[part 3 of 4: packages /PDU to /ComponentTypes]
AUTOSAR XML (schema 4-3-0)
package /PDU
  pdu ClampControl_KL_01_XIX_VLAN_FAS: length=8, transmission-mode-true-timing=cyclic-timing={time-offset=0.0, time-period=0.02}, unused-bit-pattern=0
    signal KL_DI_KL_58xd_XIX_ClampControl_KL_01_XIX_VLAN_FAS: start 12, 8 bit, little-endian, data-type-policy=OVERRIDE, i-signal-type=PRIMITIVE, init-value=254, base-type=BT_KL_DI_KL_58xd, invalid-value=Invalid_KL_DI_KL_58xd_XIX_ClampControl_KL_01_XIX_VLAN_FAS:255, compu {phys=raw for raw 0..253, 255=Cxff_Fehler, 254=Cxfe_Init}, range phys 0..253, raw 0..255, transfer-property=PENDING, to Zone_VR(timeout 0.5 s)  # Klemme 58xd Display- und Funkltionsbeleuchtung
    signal KL_DI_KL_58xs_XIX_ClampControl_KL_01_XIX_VLAN_FAS: start 20, 7 bit, little-endian, data-type-policy=OVERRIDE, i-signal-type=PRIMITIVE, init-value=126, base-type=BT_KL_DI_KL_58xs, invalid-value=Invalid_KL_DI_KL_58xs_XIX_ClampControl_KL_01_XIX_VLAN_FAS:127, compu {phys=raw for raw 0..100, 127=Cx7f_Fehler, 126=Cx7e_Init}, range phys 0..100, raw 0..127, transfer-property=PENDING, to Zone_VR(timeout 0.5 s)  # Klemme 58xs Suchbeleuchtung
    signal KL_KST_KL_15_XIX_ClampControl_KL_01_XIX_VLAN_FAS: start 27, 1 bit, little-endian, data-type-policy=OVERRIDE, i-signal-type=PRIMITIVE, init-value=0, base-type=BT_KL_KST_KL_15, compu {0=Cx0_Aus, 1=Cx1_Ein}, range raw 0..1, transfer-property=PENDING, to Zone_VR(timeout 0.5 s)  # Klemme 15: Zuendung (SW-Kl.15) (geroutet)
  pdu ClimateControl_01_XIX_VLAN_FAS: length=64, minimum-delay=0.01, transmission-mode-true-timing={cyclic-timing={time-offset=0.0, time-period=0.1}, event-controlled-timing={number-of-repetitions=0, repetition-period=0.0}}, unused-bit-pattern=0
    signal KL_Temp_Soll_hr_XIX_ClimateControl_01_XIX_VLAN_FAS: start 13, 5 bit, little-endian, data-type-policy=OVERRIDE, i-signal-type=PRIMITIVE, init-value=31, base-type=BT_KL_Temp_Soll_hr, compu {phys=raw*0.5+15.5 for raw 0..29, 30=Cx1e_Klima_OFF, 31=Cx1f_Init; unit Unit_DegreCelsi}, range phys 15.5..30 Unit_DegreCelsi, raw 0..31, unit=Unit_DegreCelsi, transfer-property=PENDING  # Eingestellte Solltemperatur hinten rechts für verteilte Komfortfunktionen
    signal KL_Temp_Soll_vl_XIX_ClimateControl_01_XIX_VLAN_FAS: start 18, 5 bit, little-endian, data-type-policy=OVERRIDE, i-signal-type=PRIMITIVE, init-value=31, base-type=BT_KL_Temp_Soll_vl, compu {phys=raw*0.5+15.5 for raw 0..29, 30=Cx1e_Klima_OFF, 31=Cx1f_Init; unit Unit_DegreCelsi}, range phys 15.5..30 Unit_DegreCelsi, raw 0..31, unit=Unit_DegreCelsi, transfer-property=PENDING  # Eingestellte Solltemperatur vorne links für verteilte Komfortfunktionen
    signal KL_Temp_Soll_vr_XIX_ClimateControl_01_XIX_VLAN_FAS: start 23, 5 bit, little-endian, data-type-policy=OVERRIDE, i-signal-type=PRIMITIVE, init-value=31, base-type=BT_KL_Temp_Soll_vr, compu {phys=raw*0.5+15.5 for raw 0..29, 31=Cx1f_Init, 30=Cx1e_Klima_OFF; unit Unit_DegreCelsi}, range phys 15.5..30 Unit_DegreCelsi, raw 0..31, unit=Unit_DegreCelsi, transfer-property=PENDING  # Eingestellte Solltemperatur vorne rechts für verteilte Komfortfunktionen
    signal KL_Umluftklappe_Status_XIX_ClimateControl_01_XIX_VLAN_FAS: start 28, 4 bit, little-endian, data-type-policy=OVERRIDE, i-signal-type=PRIMITIVE, init-value=14, base-type=BT_KL_Umluftklappe_Status, invalid-value=Invalid_KL_Umluftklappe_Status_XIX_ClimateControl_01_XIX_VLAN_FAS:15, compu {15=Cxf_Fehler, 8=Cx8_Teilumluft_80, 1=Cx1_Teilumluft_10, 0=Cx0_Frischluft, 9=Cx9_Teilumluft_90, 6=Cx6_Teilumluft_60, 14=Cxe_Init, 10=Cxa_Umluft, 4=Cx4_Teilumluft_40, 2=Cx2_Teilumluft_20, 7=Cx7_Teilumluft_70, 5=Cx5_Teilumluft_50, 3=Cx3_Teilumluft_30}, range raw 0..15, transfer-property=PENDING  # Status Umluftklappe
    signal KL_Innen_Temp_XIX_ClimateControl_01_XIX_VLAN_FAS: start 32, 8 bit, little-endian, data-type-policy=OVERRIDE, i-signal-type=PRIMITIVE, init-value=254, base-type=BT_KL_Innen_Temp, invalid-value=Invalid_KL_Innen_Temp_XIX_ClimateControl_01_XIX_VLAN_FAS:255, compu {phys=raw*0.5-50 for raw 0..252, 255=Cxff_Fehler, 254=Cxfe_nicht_verfuegbar, 253=Cxfd_nicht_verbaut; unit Unit_DegreCelsi}, range phys -50..76 Unit_DegreCelsi, raw 0..255, unit=Unit_DegreCelsi, transfer-property=PENDING  # Innentemperatur
    signal KL_I_Geblaese_XIX_ClimateControl_01_XIX_VLAN_FAS: start 40, 8 bit, little-endian, data-type-policy=OVERRIDE, i-signal-type=PRIMITIVE, init-value=0, base-type=BT_KL_I_Geblaese, invalid-value=Invalid_KL_I_Geblaese_XIX_ClimateControl_01_XIX_VLAN_FAS:255, compu {phys=raw*0.25 for raw 0..254, 255=Cxff_Fehler; unit Unit_Amper}, range phys 0..63.5 Unit_Amper, raw 0..255, unit=Unit_Amper, transfer-property=PENDING  # Stromaufnahme Gebläse
    signal ClActFan_perc_BlowerTarVal_S_XIX_ClimateControl_01_XIX_VLAN_FAS: start 48, 8 bit, little-endian, data-type-policy=OVERRIDE, i-signal-type=PRIMITIVE, init-value=0, base-type=BT_ClActFan_perc_BlowerTarVal_S, compu {phys=raw for raw 0..255; unit Unit_PerCent}, range phys 0..255 Unit_PerCent, raw 0..255, unit=Unit_PerCent, transfer-property=PENDING, to Zone_VR(timeout 1 s)  # Soll Wert des BLDC in Prozent
    signal ClHmi_st_StDfrst_S_XIX_ClimateControl_01_XIX_VLAN_FAS: start 56, 8 bit, little-endian, data-type-policy=OVERRIDE, i-signal-type=PRIMITIVE, init-value=0, base-type=BT_ClHmi_st_StDfrst_S, compu {phys=raw for raw 0..255; unit Unit_None}, range phys 0..255 Unit_None, raw 0..255, unit=Unit_None, transfer-property=PENDING, to Zone_VR(timeout 1 s)  # Aktueller Status Defrost UX
    signal ClHmi_T_CurTempFrntLe_S_XIX_ClimateControl_01_XIX_VLAN_FAS: start 64, 8 bit, little-endian, data-type-policy=OVERRIDE, i-signal-type=PRIMITIVE, init-value=0, base-type=BT_ClHmi_T_CurTempFrntLe_S, compu {phys=raw*0.1+10 for raw 0..255; unit Unit_DegreCelsi}, range phys 10..35.5 Unit_DegreCelsi, raw 0..255, unit=Unit_DegreCelsi, transfer-property=PENDING, to Zone_VR(timeout 1 s)  # Aktuell eingestellte Temperatur VL
    signal ClHmi_T_CurTempFrntRi_S_XIX_ClimateControl_01_XIX_VLAN_FAS: start 72, 8 bit, little-endian, data-type-policy=OVERRIDE, i-signal-type=PRIMITIVE, init-value=0, base-type=BT_ClHmi_T_CurTempFrntRi_S, compu {phys=raw*0.1+10 for raw 0..255; unit Unit_DegreCelsi}, range phys 10..35.5 Unit_DegreCelsi, raw 0..255, unit=Unit_DegreCelsi, transfer-property=PENDING, to Zone_VR(timeout 1 s)  # Aktuell eingestellte Temperatur VR
    signal ClHmi_T_CurTempRearLe_S_XIX_ClimateControl_01_XIX_VLAN_FAS: start 80, 8 bit, little-endian, data-type-policy=OVERRIDE, i-signal-type=PRIMITIVE, init-value=0, base-type=BT_ClHmi_T_CurTempRearLe_S, compu {phys=raw*0.1+10 for raw 0..255; unit Unit_DegreCelsi}, range phys 10..35.5 Unit_DegreCelsi, raw 0..255, unit=Unit_DegreCelsi, transfer-property=PENDING, to Zone_VR(timeout 1 s)  # Aktuell eingestellte Temperatur HL
    signal ClHmi_T_CurTempRearRi_S_XIX_ClimateControl_01_XIX_VLAN_FAS: start 88, 8 bit, little-endian, data-type-policy=OVERRIDE, i-signal-type=PRIMITIVE, init-value=0, base-type=BT_ClHmi_T_CurTempRearRi_S, compu {phys=raw*0.1+10 for raw 0..255; unit Unit_DegreCelsi}, range phys 10..35.5 Unit_DegreCelsi, raw 0..255, unit=Unit_DegreCelsi, transfer-property=PENDING, to Zone_VR(timeout 1 s)  # Aktuell eingestellte Temperatur HR
    signal KL_BT_Tuer_geoeffnet_XIX_ClimateControl_01_XIX_VLAN_FAS: start 96, 1 bit, little-endian, data-type-policy=OVERRIDE, i-signal-type=PRIMITIVE, init-value=0, base-type=BT_KL_BT_Tuer_geoeffnet, compu {1=Cx1_offen, 0=Cx0_geschlossen}, range raw 0..1, transfer-property=TRIGGERED-ON-CHANGE-WITHOUT-REPETITION  # Status Beifahrertuer (Routing)
    signal KL_FT_Tuer_geoeffnet_XIX_ClimateControl_01_XIX_VLAN_FAS: start 97, 1 bit, little-endian, data-type-policy=OVERRIDE, i-signal-type=PRIMITIVE, init-value=0, base-type=BT_KL_FT_Tuer_geoeffnet, compu {1=Cx1_offen, 0=Cx0_geschlossen}, range raw 0..1, transfer-property=TRIGGERED-ON-CHANGE-WITHOUT-REPETITION  # Status Tuer_offen (Routing)
    signal KL_HBFS_Tuer_geoeffnet_XIX_ClimateControl_01_XIX_VLAN_FAS: start 98, 1 bit, little-endian, data-type-policy=OVERRIDE, i-signal-type=PRIMITIVE, init-value=0, base-type=BT_KL_HBFS_Tuer_geoeffnet, compu {0=Cx0_geschlossen, 1=Cx1_offen}, range raw 0..1, transfer-property=TRIGGERED-ON-CHANGE-WITHOUT-REPETITION  # Status Beifahrertuer hinten (Routing)
    signal KL_HFS_Tuer_geoeffnet_XIX_ClimateControl_01_XIX_VLAN_FAS: start 99, 1 bit, little-endian, data-type-policy=OVERRIDE, i-signal-type=PRIMITIVE, init-value=0, base-type=BT_KL_HFS_Tuer_geoeffnet, compu {1=Cx1_offen, 0=Cx0_geschlossen}, range raw 0..1, transfer-property=TRIGGERED-ON-CHANGE-WITHOUT-REPETITION  # Status Fahrertuer hinten (Routing)
    signal KL_Geblaese_Status_XIX_ClimateControl_01_XIX_VLAN_FAS: start 100, 4 bit, little-endian, data-type-policy=OVERRIDE, i-signal-type=PRIMITIVE, init-value=14, base-type=BT_KL_Geblaese_Status, invalid-value=Invalid_KL_Geblaese_Status_XIX_ClimateControl_01_XIX_VLAN_FAS:15, compu {15=Cxf_Fehler, 14=Cxe_Init, 0=Cx0_Geblaese_aus, 1=Cx1_Geblaesestufe_10, 2=Cx2_Geblaesestufe_20, 3=Cx3_Geblaesestufe_30, 4=Cx4_Geblaesestufe_40, 5=Cx5_Geblaesestufe_50, 6=Cx6_Geblaesestufe_60, 7=Cx7_Geblaesestufe_70, 8=Cx8_Geblaesestufe_80, 9=Cx9_Geblaesestufe_90, 10=Cxa_Geblaesestufe_100}, range raw 0..15, transfer-property=PENDING  # Status Geblaese
    signal KL_Temp_Soll_hl_XIX_ClimateControl_01_XIX_VLAN_FAS: start 104, 5 bit, little-endian, data-type-policy=OVERRIDE, i-signal-type=PRIMITIVE, init-value=31, base-type=BT_KL_Temp_Soll_hl, compu {phys=raw*0.5+15.5 for raw 0..29, 31=Cx1f_Init, 30=Cx1e_Klima_OFF; unit Unit_DegreCelsi}, range phys 15.5..30 Unit_DegreCelsi, raw 0..31, unit=Unit_DegreCelsi, transfer-property=PENDING  # Eingestellte Solltemperatur hinten links für verteilte Komfortfunktionen
    signal ClHmi_st_BtnDfrst_S_XIX_ClimateControl_01_XIX_VLAN_FAS: start 109, 8 bit, little-endian, data-type-policy=OVERRIDE, i-signal-type=PRIMITIVE, init-value=0, base-type=BT_ClHmi_st_BtnDfrst_S, compu {phys=raw for raw 0..255; unit Unit_None}, range phys 0..255 Unit_None, raw 0..255, unit=Unit_None, transfer-property=PENDING  # Tastendruck Defrost
    signal ClAct_perc_FlapDfrstTarVal_XIX_ClimateControl_01_XIX_VLAN_FAS: start 117, 8 bit, little-endian, data-type-policy=OVERRIDE, i-signal-type=PRIMITIVE, init-value=0, base-type=BT_ClAct_perc_FlapDfrstTarVal, compu {phys=raw for raw 0..255; unit Unit_PerCent}, range phys 0..255 Unit_PerCent, raw 0..255, unit=Unit_PerCent, transfer-property=PENDING, to Zone_VR(timeout 1 s)  # Soll-Wert der Stellklappe Defrost in Prozent
    signal ClAct_perc_FlapTFrntLeTarVal_XIX_ClimateControl_01_XIX_VLAN_FAS: start 125, 8 bit, little-endian, data-type-policy=OVERRIDE, i-signal-type=PRIMITIVE, init-value=0, base-type=BT_ClAct_perc_FlapTFrntLeTarVal, compu {phys=raw for raw 0..255; unit Unit_PerCent}, range phys 0..255 Unit_PerCent, raw 0..255, unit=Unit_PerCent, transfer-property=PENDING, to Zone_VR(timeout 1 s)  # Soll-Wert der Stellklappe Temp VL in Prozent
    signal ClAct_perc_FlapTFrntRiTarVal_XIX_ClimateControl_01_XIX_VLAN_FAS: start 133, 8 bit, little-endian, data-type-policy=OVERRIDE, i-signal-type=PRIMITIVE, init-value=0, base-type=BT_ClAct_perc_FlapTFrntRiTarVal, compu {phys=raw for raw 0..255; unit Unit_PerCent}, range phys 0..255 Unit_PerCent, raw 0..255, unit=Unit_PerCent, transfer-property=PENDING, to Zone_VR(timeout 1 s)  # Soll-Wert der Stellklappe Temp VR in Prozent
    signal ClAct_perc_FlapTRearLeTarVal_XIX_ClimateControl_01_XIX_VLAN_FAS: start 141, 8 bit, little-endian, data-type-policy=OVERRIDE, i-signal-type=PRIMITIVE, init-value=0, base-type=BT_ClAct_perc_FlapTRearLeTarVal, compu {phys=raw for raw 0..255; unit Unit_PerCent}, range phys 0..255 Unit_PerCent, raw 0..255, unit=Unit_PerCent, transfer-property=PENDING, to Zone_VR(timeout 1 s)  # Soll-Wert der Stellklappe Temp HL in Prozent
    signal ClAct_perc_FlapTRearRiTarVal_XIX_ClimateControl_01_XIX_VLAN_FAS: start 149, 8 bit, little-endian, data-type-policy=OVERRIDE, i-signal-type=PRIMITIVE, init-value=0, base-type=BT_ClAct_perc_FlapTRearRiTarVal, compu {phys=raw for raw 0..255; unit Unit_PerCent}, range phys 0..255 Unit_PerCent, raw 0..255, unit=Unit_PerCent, transfer-property=PENDING, to Zone_VR(timeout 1 s)  # Soll-Wert der Stellklappe Temp HR in Prozent
    signal ClSens_SetBit1_S_XIX_ClimateControl_01_XIX_VLAN_FAS: start 157, 16 bit, little-endian, data-type-policy=OVERRIDE, i-signal-type=PRIMITIVE, init-value=0, base-type=BT_ClSens_SetBit1_S, compu {phys=raw for raw 0..65535; unit Unit_None}, range phys 0..65535 Unit_None, raw 0..65535, unit=Unit_None, transfer-property=PENDING, to Zone_VR(timeout 1 s)  # Aktivierung Climate Funktion
    signal ClSens_SetBit2_S_XIX_ClimateControl_01_XIX_VLAN_FAS: start 173, 16 bit, little-endian, data-type-policy=OVERRIDE, i-signal-type=PRIMITIVE, init-value=0, base-type=BT_ClSens_SetBit2_S, compu {phys=raw for raw 0..65535; unit Unit_None}, range phys 0..65535 Unit_None, raw 0..65535, unit=Unit_None, transfer-property=PENDING, to Zone_VR(timeout 1 s)  # Aktivierung Climate Funktion
    signal ClHmi_st_ClInfo_S_XIX_ClimateControl_01_XIX_VLAN_FAS: start 189, 8 bit, little-endian, data-type-policy=OVERRIDE, i-signal-type=PRIMITIVE, init-value=0, base-type=BT_ClHmi_st_ClInfo_S, invalid-value=Invalid_ClHmi_st_ClInfo_S_XIX_ClimateControl_01_XIX_VLAN_FAS:15, compu {15=Cxf_Fehler, 3=Cx3_HEATING, 0=Cx0_OFF, 2=Cx2_VENTILATION, 1=Cx1_COOLING}, range raw 0..15, transfer-property=TRIGGERED-ON-CHANGE-WITHOUT-REPETITION  # Status Climatisation
    signal ClStm_OpState_XIX_ClimateControl_01_XIX_VLAN_FAS: start 197, 8 bit, little-endian, data-type-policy=OVERRIDE, i-signal-type=PRIMITIVE, init-value=0, base-type=BT_ClStm_OpState, compu {phys=raw for raw 0..255; unit Unit_None}, range phys 0..255 Unit_None, raw 0..255, unit=Unit_None, transfer-property=PENDING, to Zone_VR(timeout 1 s)  # Aktueller Zustand der Klimasoftware
  pdu ClimateControl_02_XIX_VLAN_FAS: length=64, minimum-delay=0.005, transmission-mode-true-timing={cyclic-timing={time-offset=0.0, time-period=0.02}, event-controlled-timing={number-of-repetitions=0, repetition-period=0.0}}, unused-bit-pattern=0
    signal ClSensUIF_st_State_S_XIX_ClimateControl_02_XIX_VLAN_FAS: start 12, 8 bit, little-endian, data-type-policy=OVERRIDE, i-signal-type=PRIMITIVE, init-value=0, base-type=BT_ClSensUIF_st_State_S, compu {phys=raw for raw 0..255; unit Unit_None}, range phys 0..255 Unit_None, raw 0..255, unit=Unit_None, transfer-property=PENDING  # Status des UIF Sensors
    signal ClSensUIF_T_FilUIF_S_XIX_ClimateControl_02_XIX_VLAN_FAS: start 20, 16 bit, little-endian, data-type-policy=OVERRIDE, i-signal-type=PRIMITIVE, init-value=0, base-type=BT_ClSensUIF_T_FilUIF_S, compu {phys=raw*0.0625-2048 for raw 0..65520; unit Unit_DegreCelsi}, range phys -2048..2047 Unit_DegreCelsi, raw 0..65520, unit=Unit_DegreCelsi, transfer-property=PENDING  # Gefilterte Temperatur des UIF
    signal ClSensUIF_T_ValUIF_S_XIX_ClimateControl_02_XIX_VLAN_FAS: start 36, 16 bit, little-endian, data-type-policy=OVERRIDE, i-signal-type=PRIMITIVE, init-value=0, base-type=BT_ClSensUIF_T_ValUIF_S, compu {phys=raw*0.0625-2048 for raw 0..65520; unit Unit_DegreCelsi}, range phys -2048..2047 Unit_DegreCelsi, raw 0..65520, unit=Unit_DegreCelsi, transfer-property=PENDING  # Aktuelle Temperatur des UIF
    signal ClSensTemp_T_TempKGFrnt_S_XIX_ClimateControl_02_XIX_VLAN_FAS: start 52, 16 bit, little-endian, data-type-policy=OVERRIDE, i-signal-type=PRIMITIVE, init-value=0, base-type=BT_ClSensTemp_T_TempKGFrnt_S, compu {phys=raw*0.0625-2048 for raw 0..65520; unit Unit_DegreCelsi}, range phys -2048..2047 Unit_DegreCelsi, raw 0..65520, unit=Unit_DegreCelsi, transfer-property=PENDING  # Aktueller Wert diskreter Temperatursensor
    signal ClAct_perc_FlapDfrstCurVal_S_XIX_ClimateControl_02_XIX_VLAN_FAS: start 68, 8 bit, little-endian, data-type-policy=OVERRIDE, i-signal-type=PRIMITIVE, init-value=0, base-type=BT_ClAct_perc_FlapDfrstCurVal_S, compu {phys=raw for raw 0..255; unit Unit_PerCent}, range phys 0..255 Unit_PerCent, raw 0..255, unit=Unit_PerCent, transfer-property=PENDING  # Aktueller Wert der Stellklappe Defrost in Prozent
    signal ClAct_perc_FlapTFrntLeCurVal_XIX_ClimateControl_02_XIX_VLAN_FAS: start 76, 8 bit, little-endian, data-type-policy=OVERRIDE, i-signal-type=PRIMITIVE, init-value=0, base-type=BT_ClAct_perc_FlapTFrntLeCurVal, compu {phys=raw for raw 0..255; unit Unit_PerCent}, range phys 0..255 Unit_PerCent, raw 0..255, unit=Unit_PerCent, transfer-property=PENDING  # Aktueller Wert der Stellklappe Temp VL in Prozent
    signal ClAct_perc_FlapTFrntRiCurVal_XIX_ClimateControl_02_XIX_VLAN_FAS: start 84, 8 bit, little-endian, data-type-policy=OVERRIDE, i-signal-type=PRIMITIVE, init-value=0, base-type=BT_ClAct_perc_FlapTFrntRiCurVal, compu {phys=raw for raw 0..255; unit Unit_PerCent}, range phys 0..255 Unit_PerCent, raw 0..255, unit=Unit_PerCent, transfer-property=PENDING  # Aktueller Wert der Stellklappe Temp VR in Prozent
    signal ClAct_perc_FlapTRearLeCurVal_XIX_ClimateControl_02_XIX_VLAN_FAS: start 92, 8 bit, little-endian, data-type-policy=OVERRIDE, i-signal-type=PRIMITIVE, init-value=0, base-type=BT_ClAct_perc_FlapTRearLeCurVal, compu {phys=raw for raw 0..255; unit Unit_PerCent}, range phys 0..255 Unit_PerCent, raw 0..255, unit=Unit_PerCent, transfer-property=PENDING  # Aktueller Wert der Stellklappe Temp HL in Prozent
    signal ClAct_perc_FlapTRearRiCurVal_XIX_ClimateControl_02_XIX_VLAN_FAS: start 100, 8 bit, little-endian, data-type-policy=OVERRIDE, i-signal-type=PRIMITIVE, init-value=0, base-type=BT_ClAct_perc_FlapTRearRiCurVal, compu {phys=raw for raw 0..255; unit Unit_PerCent}, range phys 0..255 Unit_PerCent, raw 0..255, unit=Unit_PerCent, transfer-property=PENDING  # Aktueller Wert der Stellklappe Temp HR in Prozent
    signal ClAct_st_FlapDfrst_S_XIX_ClimateControl_02_XIX_VLAN_FAS: start 108, 8 bit, little-endian, data-type-policy=OVERRIDE, i-signal-type=PRIMITIVE, init-value=0, base-type=BT_ClAct_st_FlapDfrst_S, compu {phys=raw for raw 0..255; unit Unit_None}, range phys 0..255 Unit_None, raw 0..255, unit=Unit_None, transfer-property=PENDING  # Status der Stellklappe Defrost
    signal ClAct_st_FlapTempFrntLe_S_XIX_ClimateControl_02_XIX_VLAN_FAS: start 116, 8 bit, little-endian, data-type-policy=OVERRIDE, i-signal-type=PRIMITIVE, init-value=0, base-type=BT_ClAct_st_FlapTempFrntLe_S, compu {phys=raw for raw 0..255; unit Unit_None}, range phys 0..255 Unit_None, raw 0..255, unit=Unit_None, transfer-property=PENDING  # Status der Stellklappe Temp VL
    signal ClAct_st_FlapTempFrntRi_S_XIX_ClimateControl_02_XIX_VLAN_FAS: start 124, 8 bit, little-endian, data-type-policy=OVERRIDE, i-signal-type=PRIMITIVE, init-value=0, base-type=BT_ClAct_st_FlapTempFrntRi_S, compu {phys=raw for raw 0..255; unit Unit_None}, range phys 0..255 Unit_None, raw 0..255, unit=Unit_None, transfer-property=PENDING  # Status der Stellklappe Temp VR
    signal ClAct_st_FlapTempRearLe_S_XIX_ClimateControl_02_XIX_VLAN_FAS: start 132, 8 bit, little-endian, data-type-policy=OVERRIDE, i-signal-type=PRIMITIVE, init-value=0, base-type=BT_ClAct_st_FlapTempRearLe_S, compu {phys=raw for raw 0..255; unit Unit_None}, range phys 0..255 Unit_None, raw 0..255, unit=Unit_None, transfer-property=PENDING  # Status der Stellklappe Temp HL
    signal ClAct_st_FlapTRearRiDfrst_XIX_ClimateControl_02_XIX_VLAN_FAS: start 140, 8 bit, little-endian, data-type-policy=OVERRIDE, i-signal-type=PRIMITIVE, init-value=0, base-type=BT_ClAct_st_FlapTRearRiDfrst, compu {phys=raw for raw 0..255; unit Unit_None}, range phys 0..255 Unit_None, raw 0..255, unit=Unit_None, transfer-property=PENDING  # Status der Stellklappe Temp HR
    signal ClActFan_perc_BlowerCurVal_S_XIX_ClimateControl_02_XIX_VLAN_FAS: start 148, 8 bit, little-endian, data-type-policy=OVERRIDE, i-signal-type=PRIMITIVE, init-value=0, base-type=BT_ClActFan_perc_BlowerCurVal_S, compu {phys=raw for raw 0..255; unit Unit_PerCent}, range phys 0..255 Unit_PerCent, raw 0..255, unit=Unit_PerCent, transfer-property=PENDING  # Aktueller Wert des BLDC in Prozent
    signal ClActFan_st_BlowerSt_S_XIX_ClimateControl_02_XIX_VLAN_FAS: start 156, 8 bit, little-endian, data-type-policy=OVERRIDE, i-signal-type=PRIMITIVE, init-value=0, base-type=BT_ClActFan_st_BlowerSt_S, compu {phys=raw for raw 0..255; unit Unit_None}, range phys 0..255 Unit_None, raw 0..255, unit=Unit_None, transfer-property=PENDING  # Status des BLDC (Blower)
    signal ClHmi_SetBit1_S_XIX_ClimateControl_02_XIX_VLAN_FAS: start 164, 16 bit, little-endian, data-type-policy=OVERRIDE, i-signal-type=PRIMITIVE, init-value=0, base-type=BT_ClHmi_SetBit1_S, compu {phys=raw for raw 0..65535; unit Unit_None}, range phys 0..65535 Unit_None, raw 0..65535, unit=Unit_None, transfer-property=PENDING  # Aktivierung Climate Funktion
    signal ClHmi_SetBit2_S_XIX_ClimateControl_02_XIX_VLAN_FAS: start 180, 16 bit, little-endian, data-type-policy=OVERRIDE, i-signal-type=PRIMITIVE, init-value=0, base-type=BT_ClHmi_SetBit2_S, compu {phys=raw for raw 0..65535; unit Unit_None}, range phys 0..65535 Unit_None, raw 0..65535, unit=Unit_None, transfer-property=PENDING  # Aktivierung Climate Funktion
    signal ClCcpRear_no_SetDfrst_S_XIX_ClimateControl_02_XIX_VLAN_FAS: start 196, 8 bit, little-endian, data-type-policy=OVERRIDE, i-signal-type=PRIMITIVE, init-value=0, base-type=BT_ClCcpRear_no_SetDfrst_S, compu {phys=raw for raw 0..255}, range phys 0..255, raw 0..255, transfer-property=TRIGGERED-ON-CHANGE-WITHOUT-REPETITION  # Aktivierungstrigger Defrost über LIN Bedienpanel
    signal ClCcpRear_no_TarDfrst_S_XIX_ClimateControl_02_XIX_VLAN_FAS: start 204, 8 bit, little-endian, data-type-policy=OVERRIDE, i-signal-type=PRIMITIVE, init-value=0, base-type=BT_ClCcpRear_no_TarDfrst_S, compu {phys=raw for raw 0..255}, range phys 0..255, raw 0..255, transfer-property=TRIGGERED-ON-CHANGE-WITHOUT-REPETITION  # Aktivierungstarget Defrost über LIN Bedienpanel
    signal ClCcpRear_T_TarTempLe_XIX_ClimateControl_02_XIX_VLAN_FAS: start 212, 8 bit, little-endian, data-type-policy=OVERRIDE, i-signal-type=PRIMITIVE, init-value=0, base-type=BT_ClCcpRear_T_TarTempLe, compu {phys=raw*0.1+10 for raw 0..255; unit Unit_DegreCelsi}, range phys 10..35.5 Unit_DegreCelsi, raw 0..255, unit=Unit_DegreCelsi, transfer-property=PENDING  # Temperatur Hinten Links über LIN Bedienpanel
    signal ClCcpRear_T_TarTempRi_XIX_ClimateControl_02_XIX_VLAN_FAS: start 220, 8 bit, little-endian, data-type-policy=OVERRIDE, i-signal-type=PRIMITIVE, init-value=0, base-type=BT_ClCcpRear_T_TarTempRi, compu {phys=raw*0.1+10 for raw 0..255; unit Unit_DegreCelsi}, range phys 10..35.5 Unit_DegreCelsi, raw 0..255, unit=Unit_DegreCelsi, transfer-property=PENDING  # Temperatur Hinten Rechts über LIN Bedienpanel
  pdu KN_Zone_VR_XIX_VLAN_FAS: length=16, unused-bit-pattern=0
    signal Zone_VR_SNI_10_XIX_KN_Zone_VR_XIX_VLAN_FAS: start 18, 10 bit, little-endian, data-type-policy=OVERRIDE, i-signal-type=PRIMITIVE, init-value=271, base-type=BT_Zone_VR_SNI_10, compu {phys=raw for raw 0..1023}, range phys 0..1023, raw 0..1023, transfer-property=TRIGGERED  # Source Node-Identifier (SNI) identifiziert den Sender der NM-Botschaft (Knotenadresse) eindeutig im Fahrzeug
  pdu TME_01_XIX_VLAN_FAS: length=64, unused-bit-pattern=0
    signal TME_T_OutsideAirTemp_raw_XIX_TME_01_XIX_VLAN_FAS: start 12, 16 bit, little-endian, data-type-policy=OVERRIDE, i-signal-type=PRIMITIVE, init-value=0, base-type=BT_TME_T_OutsideAirTemp_raw, compu {phys=raw*0.1-40 for raw 0..1900; unit Unit_DegreCelsi}, range phys -40..150 Unit_DegreCelsi, raw 0..1900, unit=Unit_DegreCelsi, transfer-property=TRIGGERED  # Rohwert des Außentemperatursensors
package /IPDUGroup
  8 x i signal i pdu group:
    Zone_VR_XIX_VLAN_FAS_Rx: communication-direction=IN, communication-mode=CAN_Receive_All, i-signal-i-pdus=[ClampControl_KL_01_XIX_VLAN_FAS, ClimateControl_01_XIX_VLAN_FAS]
    Zone_VR_XIX_VLAN_FAS_Tx: communication-direction=OUT, communication-mode=CAN_Transmit_All, i-signal-i-pdus=[KN_Zone_VR_XIX_VLAN_FAS, ClimateControl_02_XIX_VLAN_FAS, TME_01_XIX_VLAN_FAS]
    Zone_VR_XIX_Zone_VR_LIN06_Rx: communication-direction=IN, communication-mode=CAN_Receive_All, i-signal-i-pdus=[KPHs_01_XIX_Zone_VR_LIN06, KPHs_02_XIX_Zone_VR_LIN06]
    Zone_VR_XIX_Zone_VR_LIN06_Tx: communication-direction=OUT, communication-mode=CAN_Transmit_All, i-signal-i-pdus=[KPHe_01_XIX_Zone_VR_LIN06, KPHe_02_XIX_Zone_VR_LIN06]
    Zone_VR_XIX_Zone_VR_LIN11_Rx: communication-direction=IN, communication-mode=CAN_Receive_All
      i-signal-i-pdus:
        ACTs_106a_Status_XIX_Zone_VR_LIN11
        ACTs_109a_Status_XIX_Zone_VR_LIN11
        ACTs_105a_Status_XIX_Zone_VR_LIN11
        ACTs_104a_Status_XIX_Zone_VR_LIN11
    Zone_VR_XIX_Zone_VR_LIN11_Tx: communication-direction=OUT, communication-mode=CAN_Transmit_All
      i-signal-i-pdus:
        ACTe_105a_Control_XIX_Zone_VR_LIN11
        ACTe_109a_Control_XIX_Zone_VR_LIN11
        ACTe_104a_Control_XIX_Zone_VR_LIN11
        ACTe_106a_Control_XIX_Zone_VR_LIN11
        ACTe_100a_Broadcast_Ctrl_XIX_Zone_VR_LIN11
    Zone_VR_XIX_Zone_VR_LIN12_Rx: communication-direction=IN, communication-mode=CAN_Receive_All, i-signal-i-pdus=[BLOWERs_01_XIX_Zone_VR_LIN12, BLOWERs_02_XIX_Zone_VR_LIN12, ACTs_102f_Status_XIX_Zone_VR_LIN12]
    Zone_VR_XIX_Zone_VR_LIN12_Tx: communication-direction=OUT, communication-mode=CAN_Transmit_All
      i-signal-i-pdus:
        BLOWERe_01_XIX_Zone_VR_LIN12
        ACTe_102f_Control_XIX_Zone_VR_LIN12
        ACTe_100f_Broadcast_Ctrl_XIX_Zone_VR_LIN12
package /BaseType
  363 x base type, all with category=FIXED_LENGTH, base-type-size=8, base-type-encoding=NONE:
    BT_ACT102f_Adresse_Aktuator
    BT_ACT102f_Blockierung_aufgetreten
    BT_ACT102f_Drehrichtung
    BT_ACT102f_el_Defekt
    BT_ACT102f_Geschwindigkeitsstatus
    BT_ACT102f_Ist_Position_Aktuator
    BT_ACT102f_Notlauf_aufgetreten
    BT_ACT102f_Notlauffreigabe
    BT_ACT102f_Notlaufposition
    BT_ACT102f_Positionsvorgabe_Status
    BT_ACT102f_Reset
    BT_ACT102f_ResponseError
    BT_ACT102f_Selbsthaltemoment
    BT_ACT102f_Sonderfunktionen
    BT_ACT102f_Spulenbestromung
    BT_ACT102f_Stopmodus
    BT_ACT102f_Uebertemperatur
    BT_ACT102f_Variante
    BT_ACT102f_Verfahrrichtung
    BT_ACT102f_Versorgungsspannung
    BT_ACT104a_Adresse_Aktuator
    BT_ACT104a_Blockierung_aufgetreten
    BT_ACT104a_Drehrichtung
    BT_ACT104a_el_Defekt
    BT_ACT104a_Geschwindigkeitsstatus
    BT_ACT104a_Ist_Position_Aktuator
    BT_ACT104a_Notlauf_aufgetreten
    BT_ACT104a_Notlauffreigabe
    BT_ACT104a_Notlaufposition
    BT_ACT104a_Positionsvorgabe_Status
    BT_ACT104a_Reset
    BT_ACT104a_ResponseError
    BT_ACT104a_Selbsthaltemoment
    BT_ACT104a_Sonderfunktionen
    BT_ACT104a_Spulenbestromung
    BT_ACT104a_Stopmodus
    BT_ACT104a_Uebertemperatur
    BT_ACT104a_Variante
    BT_ACT104a_Verfahrrichtung
    BT_ACT104a_Versorgungsspannung
    BT_ACT105a_Adresse_Aktuator
    BT_ACT105a_Blockierung_aufgetreten
    BT_ACT105a_Drehrichtung
    BT_ACT105a_el_Defekt
    BT_ACT105a_Geschwindigkeitsstatus
    BT_ACT105a_Ist_Position_Aktuator
    BT_ACT105a_Notlauf_aufgetreten
    BT_ACT105a_Notlauffreigabe
    BT_ACT105a_Notlaufposition
    BT_ACT105a_Positionsvorgabe_Status
    BT_ACT105a_Reset
    BT_ACT105a_ResponseError
    BT_ACT105a_Selbsthaltemoment
    BT_ACT105a_Sonderfunktionen
    BT_ACT105a_Spulenbestromung
    BT_ACT105a_Stopmodus
    BT_ACT105a_Uebertemperatur
    BT_ACT105a_Variante
    BT_ACT105a_Verfahrrichtung
    BT_ACT105a_Versorgungsspannung
    BT_ACT106a_Adresse_Aktuator
    BT_ACT106a_Blockierung_aufgetreten
    BT_ACT106a_Drehrichtung
    BT_ACT106a_el_Defekt
    BT_ACT106a_Geschwindigkeitsstatus
    BT_ACT106a_Ist_Position_Aktuator
    BT_ACT106a_Notlauf_aufgetreten
    BT_ACT106a_Notlauffreigabe
    BT_ACT106a_Notlaufposition
    BT_ACT106a_Positionsvorgabe_Status
    BT_ACT106a_Reset
    BT_ACT106a_ResponseError
    BT_ACT106a_Selbsthaltemoment
    BT_ACT106a_Sonderfunktionen
    BT_ACT106a_Spulenbestromung
    BT_ACT106a_Stopmodus
    BT_ACT106a_Uebertemperatur
    BT_ACT106a_Variante
    BT_ACT106a_Verfahrrichtung
    BT_ACT106a_Versorgungsspannung
    BT_ACT109a_Adresse_Aktuator
    BT_ACT109a_Blockierung_aufgetreten
    BT_ACT109a_Drehrichtung
    BT_ACT109a_el_Defekt
    BT_ACT109a_Geschwindigkeitsstatus
    BT_ACT109a_Ist_Position_Aktuator
    BT_ACT109a_Notlauf_aufgetreten
    BT_ACT109a_Notlauffreigabe
    BT_ACT109a_Notlaufposition
    BT_ACT109a_Positionsvorgabe_Status
    BT_ACT109a_Reset
    BT_ACT109a_ResponseError
    BT_ACT109a_Selbsthaltemoment
    BT_ACT109a_Sonderfunktionen
    BT_ACT109a_Spulenbestromung
    BT_ACT109a_Stopmodus
    BT_ACT109a_Uebertemperatur
    BT_ACT109a_Variante
    BT_ACT109a_Verfahrrichtung
    BT_ACT109a_Versorgungsspannung
    BT_BLOWER_DIAG_FLAG1
    BT_BLOWER_DIAG_FLAG2
    BT_BLOWER_IBATT
    BT_BLOWER_ROTATION_SPEED
    BT_BLOWER_STATUS_MOTOR
    BT_BLOWER_SUPPLIER
    BT_BLOWER_TEMPERATURE
    BT_BLOWER_TORQUE
    BT_BLOWER_UBATT
    BT_BLOWER_UMOTOR
    BT_ClAct_perc_FlapDfrstCurVal_S
    BT_ClAct_perc_FlapDfrstTarVal
    BT_ClAct_perc_FlapTFrntLeCurVal
    BT_ClAct_perc_FlapTFrntLeTarVal
    BT_ClAct_perc_FlapTFrntRiCurVal
    BT_ClAct_perc_FlapTFrntRiTarVal
    BT_ClAct_perc_FlapTRearLeCurVal
    BT_ClAct_perc_FlapTRearLeTarVal
    BT_ClAct_perc_FlapTRearRiCurVal
    BT_ClAct_perc_FlapTRearRiTarVal
    BT_ClAct_st_FlapDfrst_S
    BT_ClAct_st_FlapTempFrntLe_S
    BT_ClAct_st_FlapTempFrntRi_S
    BT_ClAct_st_FlapTempRearLe_S
    BT_ClAct_st_FlapTRearRiDfrst
    BT_ClActFan_perc_BlowerCurVal_S
    BT_ClActFan_perc_BlowerTarVal_S
    BT_ClActFan_st_BlowerSt_S
    BT_ClCcpRear_no_SetDfrst_S
    BT_ClCcpRear_no_TarDfrst_S
    BT_ClCcpRear_T_TarTempLe
    BT_ClCcpRear_T_TarTempRi
    BT_ClHmi_SetBit1_S
    BT_ClHmi_SetBit2_S
    BT_ClHmi_st_BtnDfrst_S
    BT_ClHmi_st_ClInfo_S
    BT_ClHmi_st_StDfrst_S
    BT_ClHmi_T_CurTempFrntLe_S
    BT_ClHmi_T_CurTempFrntRi_S
    BT_ClHmi_T_CurTempRearLe_S
    BT_ClHmi_T_CurTempRearRi_S
    BT_ClSens_SetBit1_S
    BT_ClSens_SetBit2_S
    BT_ClSensTemp_T_TempKGFrnt_S
    BT_ClSensUIF_st_State_S
    BT_ClSensUIF_T_FilUIF_S
    BT_ClSensUIF_T_ValUIF_S
    BT_ClStm_OpState
    BT_Geblaese_ResponseError
    BT_KBT_CODE_VEHICLE
    BT_KBT_RAMP
    BT_KBT_RX_FREQUENCY
    BT_KBT_SAFETY_SPEED
    BT_KBT_SPEED
    BT_KL_BT_Tuer_geoeffnet
    BT_KL_DI_KL_58xd
    BT_KL_DI_KL_58xs
    BT_KL_FT_Tuer_geoeffnet
    BT_KL_Geblaese_Status
    BT_KL_HBFS_Tuer_geoeffnet
    BT_KL_HFS_Tuer_geoeffnet
    BT_KL_I_Geblaese
    BT_KL_Innen_Temp
    BT_KL_KST_KL_15
    BT_KL_Temp_Soll_hl
    BT_KL_Temp_Soll_hr
    BT_KL_Temp_Soll_vl
    BT_KL_Temp_Soll_vr
    BT_KL_Umluftklappe_Status
    BT_KPH_01_Init
    BT_KPH_AC
    BT_KPH_AC_max
    BT_KPH_Auto_li
    BT_KPH_Auto_re
    BT_KPH_Beduftung
    BT_KPH_ECO
    BT_KPH_ECO_links
    BT_KPH_ECO_rechts
    BT_KPH_Flaechenheizung
    BT_KPH_Geblaese_Auto_li
    BT_KPH_Geblaese_Auto_re
    BT_KPH_Geblaese_Stufe_li
    BT_KPH_Geblaese_Stufe_re
    BT_KPH_Init
    BT_KPH_Ionisator
    BT_KPH_Klima_Menue_MMI
    BT_KPH_Lautsprecher
    BT_KPH_Lokalaktiv
    BT_KPH_Luftverteilung_Auto_li
    BT_KPH_Luftverteilung_Auto_re
    BT_KPH_Luftverteilung_Mitte_li
    BT_KPH_Luftverteilung_Mitte_re
    BT_KPH_Luftverteilung_Oben_li
    BT_KPH_Luftverteilung_Oben_re
    BT_KPH_Luftverteilung_Unten_li
    BT_KPH_Luftverteilung_Unten_re
    BT_KPH_Neigungssensor
    BT_KPH_Off
    BT_KPH_Panel_Error
    BT_KPH_ResponseError
    BT_KPH_Sitzheizung_li
    BT_KPH_Sitzheizung_re
    BT_KPH_Sitzlueftung_li
    BT_KPH_Sitzlueftung_re
    BT_KPH_Status_Spannung
    BT_KPH_Sync
    BT_KPH_Tasten_Fehler
    BT_KPH_Temp_li
    BT_KPH_Temp_Platine
    BT_KPH_Temp_re
    BT_KPH_Umluft
    BT_KPH_Umprog_Sektor_Nr
    BT_KPH_Umprog_Symbol_Nr
    BT_KPHe_Auto_Toggle
    BT_KPHe_Einheit
    BT_KPHe_Fondbedienung
    BT_KPHe_Funktion_AC
    BT_KPHe_Funktion_AC_max
    BT_KPHe_Funktion_Auto_li
    BT_KPHe_Funktion_Auto_re
    BT_KPHe_Funktion_Beduftung
    BT_KPHe_Funktion_Defrost
    BT_KPHe_Funktion_ECO
    BT_KPHe_Funktion_ECO_Zone
    BT_KPHe_Funktion_Flaechenheizung
    BT_KPHe_Funktion_Frontbedienung
    BT_KPHe_Funktion_Halbkreis_li
    BT_KPHe_Funktion_Halbkreis_re
    BT_KPHe_Funktion_Ionisator
    BT_KPHe_Funktion_Kindersicherung
    BT_KPHe_Funktion_Off
    BT_KPHe_Funktion_Sync
    BT_KPHe_Funktion_Umluft
    BT_KPHe_Funktionsbeleuchtung
    BT_KPHe_Fzg_Steigung
    BT_KPHe_Geblaese_Auto_li
    BT_KPHe_Geblaese_Auto_re
    BT_KPHe_Geblaese_Begrenzung
    BT_KPHe_Geblaese_Stufe_li
    BT_KPHe_Geblaese_Stufe_re
    BT_KPHe_LCD
    BT_KPHe_Lenker_Position
    BT_KPHe_Luftverteilung_Auto_li
    BT_KPHe_Luftverteilung_Auto_re
    BT_KPHe_Luftverteilung_Mitte_li
    BT_KPHe_Luftverteilung_Mitte_re
    BT_KPHe_Luftverteilung_Oben_li
    BT_KPHe_Luftverteilung_Oben_re
    BT_KPHe_Luftverteilung_Unten_li
    BT_KPHe_Luftverteilung_Unten_re
    BT_KPHe_QBit_Steigung
    BT_KPHe_Radio_Frequenz
    BT_KPHe_Sitzheizung_li
    BT_KPHe_Sitzheizung_re
    BT_KPHe_Sitzlueftung_li
    BT_KPHe_Sitzlueftung_re
    BT_KPHe_Stellgliedtest
    BT_KPHe_Suchbeleuchtung
    BT_KPHe_Symbol_Luftmenge_li
    BT_KPHe_Symbol_Luftmenge_re
    BT_KPHe_Symbol_Luftverteilung_li
    BT_KPHe_Symbol_Luftverteilung_re
    BT_KPHe_Symbol_Sitzheizung_li
    BT_KPHe_Symbol_Sitzheizung_re
    BT_KPHe_Symbol_Sitzlueftung_li
    BT_KPHe_Symbol_Sitzlueftung_re
    BT_KPHe_Temp_li
    BT_KPHe_Temp_re
    BT_KPHe_TFT
    BT_STRG100a_Adresse
    BT_STRG100a_Clear_Event_Flags
    BT_STRG100a_Drehrichtung
    BT_STRG100a_Freig_Blockiererkennung
    BT_STRG100a_Geschwindigkeitsvorgabe
    BT_STRG100a_Notlauffreigabe
    BT_STRG100a_Notlaufposition
    BT_STRG100a_PrgDaten_speichern
    BT_STRG100a_Select_Positionsvorgabe
    BT_STRG100a_Soll_Position
    BT_STRG100a_Spulenhaltebestromung
    BT_STRG100a_Start_Position
    BT_STRG100a_Stopmodus
    BT_STRG100f_Adresse
    BT_STRG100f_Clear_Event_Flags
    BT_STRG100f_Drehrichtung
    BT_STRG100f_Freig_Blockiererkennung
    BT_STRG100f_Geschwindigkeitsvorgabe
    BT_STRG100f_Notlauffreigabe
    BT_STRG100f_Notlaufposition
    BT_STRG100f_PrgDaten_speichern
    BT_STRG100f_Select_Positionsvorgabe
    BT_STRG100f_Soll_Position
    BT_STRG100f_Spulenhaltebestromung
    BT_STRG100f_Start_Position
    BT_STRG100f_Stopmodus
    BT_STRG102f_Adresse
    BT_STRG102f_Clear_Event_Flags
    BT_STRG102f_Drehrichtung
    BT_STRG102f_Freig_Blockiererkennung
    BT_STRG102f_Geschwindigkeitsvorgabe
    BT_STRG102f_Notlauffreigabe
    BT_STRG102f_Notlaufposition
    BT_STRG102f_PrgDaten_speichern
    BT_STRG102f_Select_Positionsvorgabe
    BT_STRG102f_Soll_Position
    BT_STRG102f_Spulenhaltebestromung
    BT_STRG102f_Start_Position
    BT_STRG102f_Stopmodus
    BT_STRG104a_Adresse
    BT_STRG104a_Clear_Event_Flags
    BT_STRG104a_Drehrichtung
    BT_STRG104a_Freig_Blockiererkennung
    BT_STRG104a_Geschwindigkeitsvorgabe
    BT_STRG104a_Notlauffreigabe
    BT_STRG104a_Notlaufposition
    BT_STRG104a_PrgDaten_speichern
    BT_STRG104a_Select_Positionsvorgabe
    BT_STRG104a_Soll_Position
    BT_STRG104a_Spulenhaltebestromung
    BT_STRG104a_Start_Position
    BT_STRG104a_Stopmodus
    BT_STRG105a_Adresse
    BT_STRG105a_Clear_Event_Flags
    BT_STRG105a_Drehrichtung
    BT_STRG105a_Freig_Blockiererkennung
    BT_STRG105a_Geschwindigkeitsvorgabe
    BT_STRG105a_Notlauffreigabe
    BT_STRG105a_Notlaufposition
    BT_STRG105a_PrgDaten_speichern
    BT_STRG105a_Select_Positionsvorgabe
    BT_STRG105a_Soll_Position
    BT_STRG105a_Spulenhaltebestromung
    BT_STRG105a_Start_Position
    BT_STRG105a_Stopmodus
    BT_STRG106a_Adresse
    BT_STRG106a_Clear_Event_Flags
    BT_STRG106a_Drehrichtung
    BT_STRG106a_Freig_Blockiererkennung
    BT_STRG106a_Geschwindigkeitsvorgabe
    BT_STRG106a_Notlauffreigabe
    BT_STRG106a_Notlaufposition
    BT_STRG106a_PrgDaten_speichern
    BT_STRG106a_Select_Positionsvorgabe
    BT_STRG106a_Soll_Position
    BT_STRG106a_Spulenhaltebestromung
    BT_STRG106a_Start_Position
    BT_STRG106a_Stopmodus
    BT_STRG109a_Adresse
    BT_STRG109a_Clear_Event_Flags
    BT_STRG109a_Drehrichtung
    BT_STRG109a_Freig_Blockiererkennung
    BT_STRG109a_Geschwindigkeitsvorgabe
    BT_STRG109a_Notlauffreigabe
    BT_STRG109a_Notlaufposition
    BT_STRG109a_PrgDaten_speichern
    BT_STRG109a_Select_Positionsvorgabe
    BT_STRG109a_Soll_Position
    BT_STRG109a_Spulenhaltebestromung
    BT_STRG109a_Start_Position
    BT_STRG109a_Stopmodus
    BT_TME_T_OutsideAirTemp_raw
    BT_Zone_VR_SNI_10
    BT_SignalVoid
package /Unit
  8 x unit:
    Unit_Unit_Amper: display-name=Unit_Amper, factor-si-to-unit=1.0, physical-dimension=PD_siAmpere
    Unit_Unit_DegreCelsi: display-name=Unit_DegreCelsi, factor-si-to-unit=1.0, offset-si-to-unit=-273.2, physical-dimension=PD_siKelvin
    Unit_Unit_KiloHertz: display-name=Unit_KiloHertz, factor-si-to-unit=0.001, physical-dimension=PD_siPerSecond
    Unit_Unit_MinutInver: display-name=Unit_MinutInver, factor-si-to-unit=60.0, physical-dimension=PD_siPerSecond
    Unit_Unit_NewtoMeter: display-name=Unit_NewtoMeter, factor-si-to-unit=1.0, physical-dimension=PD_siNewtonMeter
    Unit_Unit_None: display-name=Unit_None, factor-si-to-unit=1.0, physical-dimension=PD_siNone
    Unit_Unit_PerCent: display-name=Unit_PerCent, factor-si-to-unit=1.0, physical-dimension=PD_siNone
    Unit_Unit_Volt: display-name=Unit_Volt, factor-si-to-unit=1.0, physical-dimension=PD_siVolt
package /PhysicalDimension
  6 x physical dimension:
    PD_siAmpere: current-exp=1
    PD_siKelvin: temperature-exp=1
    PD_siNewtonMeter: length-exp=2, mass-exp=1, time-exp=-2
    PD_siNone
    PD_siPerSecond: time-exp=-1
    PD_siVolt: length-exp=2, mass-exp=1, time-exp=-1, current-exp=-1
package /Interfaces
  339 x sender receiver interface:
    IF_BLOWER_TEMPERATURE
      data DE_BLOWER_TEMPERATURE: type=uint8
    IF_KBT_RAMP
      data DE_KBT_RAMP: type=uint8
    IF_KBT_RX_FREQUENCY
      data DE_KBT_RX_FREQUENCY: type=uint16
    IF_KBT_SPEED
      data DE_KBT_SPEED: type=uint8
    IF_KBT_CODE_VEHICLE
      data DE_KBT_CODE_VEHICLE: type=uint8
    IF_KBT_SAFETY_SPEED
      data DE_KBT_SAFETY_SPEED: type=uint8
    IF_BLOWER_UBATT
      data DE_BLOWER_UBATT: type=uint8
    IF_BLOWER_UMOTOR
      data DE_BLOWER_UMOTOR: type=uint8
    IF_BLOWER_SUPPLIER
      data DE_BLOWER_SUPPLIER: type=uint8
    IF_BLOWER_STATUS_MOTOR
      data DE_BLOWER_STATUS_MOTOR: type=uint8
    IF_BLOWER_ROTATION_SPEED
      data DE_BLOWER_ROTATION_SPEED: type=uint8
    IF_BLOWER_IBATT
      data DE_BLOWER_IBATT: type=uint8
    IF_BLOWER_DIAG_FLAG2
      data DE_BLOWER_DIAG_FLAG2: type=uint8
    IF_BLOWER_DIAG_FLAG1
      data DE_BLOWER_DIAG_FLAG1: type=uint8
    IF_KPHe_Funktion_Halbkreis_li
      data DE_KPHe_Funktion_Halbkreis_li: type=boolean
    IF_KPHe_Funktion_Off
      data DE_KPHe_Funktion_Off: type=boolean
    IF_KPHe_Funktion_Ionisator
      data DE_KPHe_Funktion_Ionisator: type=boolean
    IF_KPHe_Funktion_Sync
      data DE_KPHe_Funktion_Sync: type=boolean
    IF_KPHe_Funktionsbeleuchtung
      data DE_KPHe_Funktionsbeleuchtung: type=boolean
    IF_KPHe_Geblaese_Stufe_li
      data DE_KPHe_Geblaese_Stufe_li: type=uint8
    IF_KPHe_Geblaese_Stufe_re
      data DE_KPHe_Geblaese_Stufe_re: type=uint8
    IF_KPHe_Funktion_Umluft
      data DE_KPHe_Funktion_Umluft: type=boolean
    IF_KPHe_Funktion_Flaechenheizung
      data DE_KPHe_Funktion_Flaechenheizung: type=boolean
    IF_KPHe_Funktion_Halbkreis_re
      data DE_KPHe_Funktion_Halbkreis_re: type=boolean
    IF_KPH_Geblaese_Stufe_li
      data DE_KPH_Geblaese_Stufe_li: type=uint8
    IF_KPH_Geblaese_Stufe_re
      data DE_KPH_Geblaese_Stufe_re: type=uint8
    IF_KPH_AC
      data DE_KPH_AC: type=boolean
    IF_KPH_ECO
      data DE_KPH_ECO: type=boolean
    IF_KPH_Auto_li
      data DE_KPH_Auto_li: type=boolean
    IF_KPH_Auto_re
      data DE_KPH_Auto_re: type=boolean
    IF_KPH_Klima_Menue_MMI
      data DE_KPH_Klima_Menue_MMI: type=boolean
    IF_KPH_Beduftung
      data DE_KPH_Beduftung: type=boolean
    IF_KPH_Flaechenheizung
      data DE_KPH_Flaechenheizung: type=boolean
    IF_KPH_Init
      data DE_KPH_Init: type=boolean
    IF_KPH_AC_max
      data DE_KPH_AC_max: type=boolean
    IF_KPH_Ionisator
      data DE_KPH_Ionisator: type=boolean
    IF_KPHe_Funktion_AC_max
      data DE_KPHe_Funktion_AC_max: type=boolean
    IF_KPHe_Funktion_ECO
      data DE_KPHe_Funktion_ECO: type=boolean
    IF_KPHe_Funktion_Auto_li
      data DE_KPHe_Funktion_Auto_li: type=boolean
    IF_KPHe_Funktion_Auto_re
      data DE_KPHe_Funktion_Auto_re: type=boolean
    IF_KPHe_Funktion_Beduftung
      data DE_KPHe_Funktion_Beduftung: type=boolean
    IF_KPHe_Suchbeleuchtung
      data DE_KPHe_Suchbeleuchtung: type=boolean
    IF_KPHe_Sitzheizung_li
      data DE_KPHe_Sitzheizung_li: type=uint8
    IF_KPHe_Sitzheizung_re
      data DE_KPHe_Sitzheizung_re: type=uint8
    IF_KPHe_Sitzlueftung_li
      data DE_KPHe_Sitzlueftung_li: type=uint8
    IF_KPHe_Sitzlueftung_re
      data DE_KPHe_Sitzlueftung_re: type=uint8
    IF_KPHe_LCD
      data DE_KPHe_LCD: type=boolean
    IF_KPHe_TFT
      data DE_KPHe_TFT: type=boolean
    IF_KPHe_Symbol_Luftmenge_li
      data DE_KPHe_Symbol_Luftmenge_li: type=boolean
    IF_KPHe_Symbol_Luftmenge_re
      data DE_KPHe_Symbol_Luftmenge_re: type=boolean
    IF_KPHe_Symbol_Luftverteilung_li
      data DE_KPHe_Symbol_Luftverteilung_li: type=boolean
    IF_KPHe_Symbol_Luftverteilung_re
      data DE_KPHe_Symbol_Luftverteilung_re: type=boolean
    IF_KPHe_Luftverteilung_Mitte_li
      data DE_KPHe_Luftverteilung_Mitte_li: type=boolean
    IF_KPHe_Luftverteilung_Unten_li
      data DE_KPHe_Luftverteilung_Unten_li: type=boolean
    IF_KPHe_Luftverteilung_Auto_li
      data DE_KPHe_Luftverteilung_Auto_li: type=boolean
    IF_KPHe_Luftverteilung_Oben_re
      data DE_KPHe_Luftverteilung_Oben_re: type=boolean
    IF_KPHe_Luftverteilung_Mitte_re
      data DE_KPHe_Luftverteilung_Mitte_re: type=boolean
    IF_KPHe_Luftverteilung_Unten_re
      data DE_KPHe_Luftverteilung_Unten_re: type=boolean
    IF_KPHe_Luftverteilung_Auto_re
      data DE_KPHe_Luftverteilung_Auto_re: type=boolean
    IF_KPHe_Temp_li
      data DE_KPHe_Temp_li: type=uint8
    IF_KPHe_Temp_re
      data DE_KPHe_Temp_re: type=uint8
    IF_KPH_Temp_li
      data DE_KPH_Temp_li: type=uint8
    IF_KPH_Temp_re
      data DE_KPH_Temp_re: type=uint8
    IF_KPH_Sitzheizung_li
      data DE_KPH_Sitzheizung_li: type=uint8
    IF_KPH_Sitzheizung_re
      data DE_KPH_Sitzheizung_re: type=uint8
    IF_KPH_Sitzlueftung_li
      data DE_KPH_Sitzlueftung_li: type=uint8
    IF_KPH_Sitzlueftung_re
      data DE_KPH_Sitzlueftung_re: type=uint8
    IF_KPH_Temp_Platine
      data DE_KPH_Temp_Platine: type=uint8
    IF_KPHe_Luftverteilung_Oben_li
      data DE_KPHe_Luftverteilung_Oben_li: type=boolean
    IF_KPH_Lokalaktiv
      data DE_KPH_Lokalaktiv: type=boolean
    IF_KPHe_Funktion_AC
      data DE_KPHe_Funktion_AC: type=boolean
    IF_KPH_Umluft
      data DE_KPH_Umluft: type=boolean
    IF_KPH_Sync
      data DE_KPH_Sync: type=boolean
    IF_KPH_Luftverteilung_Oben_li
      data DE_KPH_Luftverteilung_Oben_li: type=boolean
    IF_KPH_Luftverteilung_Mitte_li
      data DE_KPH_Luftverteilung_Mitte_li: type=boolean
    IF_KPH_Luftverteilung_Unten_li
      data DE_KPH_Luftverteilung_Unten_li: type=boolean
    IF_KPH_Luftverteilung_Auto_li
      data DE_KPH_Luftverteilung_Auto_li: type=boolean
    IF_KPH_Luftverteilung_Oben_re
      data DE_KPH_Luftverteilung_Oben_re: type=boolean
    IF_KPH_Luftverteilung_Mitte_re
      data DE_KPH_Luftverteilung_Mitte_re: type=boolean
    IF_KPH_Luftverteilung_Unten_re
      data DE_KPH_Luftverteilung_Unten_re: type=boolean
    IF_KPH_Luftverteilung_Auto_re
      data DE_KPH_Luftverteilung_Auto_re: type=boolean
    IF_KPH_Panel_Error
      data DE_KPH_Panel_Error: type=uint8
    IF_KPH_ResponseError
      data DE_KPH_ResponseError: type=boolean
    IF_KPH_Off
      data DE_KPH_Off: type=boolean
    IF_BLOWER_TORQUE
      data DE_BLOWER_TORQUE: type=uint16
    IF_KPHe_Funktion_Kindersicherung
      data DE_KPHe_Funktion_Kindersicherung: type=boolean
    IF_KPHe_Funktion_Frontbedienung
      data DE_KPHe_Funktion_Frontbedienung: type=boolean
    IF_KPHe_Lenker_Position
      data DE_KPHe_Lenker_Position: type=boolean
    IF_KPHe_Einheit
      data DE_KPHe_Einheit: type=boolean
    IF_KPHe_Stellgliedtest
      data DE_KPHe_Stellgliedtest: type=boolean
    IF_KPHe_Symbol_Sitzlueftung_li
      data DE_KPHe_Symbol_Sitzlueftung_li: type=boolean
    IF_KPHe_Fondbedienung
      data DE_KPHe_Fondbedienung: type=boolean
    IF_KPHe_Symbol_Sitzheizung_li
      data DE_KPHe_Symbol_Sitzheizung_li: type=boolean
    IF_KPHe_Symbol_Sitzheizung_re
      data DE_KPHe_Symbol_Sitzheizung_re: type=boolean
    IF_KPHe_Symbol_Sitzlueftung_re
      data DE_KPHe_Symbol_Sitzlueftung_re: type=boolean
    IF_KPHe_Geblaese_Begrenzung
      data DE_KPHe_Geblaese_Begrenzung: type=boolean
    IF_KPHe_Geblaese_Auto_re
      data DE_KPHe_Geblaese_Auto_re: type=boolean
    IF_KPHe_Geblaese_Auto_li
      data DE_KPHe_Geblaese_Auto_li: type=boolean
    IF_KPH_Status_Spannung
      data DE_KPH_Status_Spannung: type=uint8
    IF_KPH_Tasten_Fehler
      data DE_KPH_Tasten_Fehler: type=boolean
    IF_KPH_Geblaese_Auto_li
      data DE_KPH_Geblaese_Auto_li: type=boolean
    IF_KPH_Geblaese_Auto_re
      data DE_KPH_Geblaese_Auto_re: type=boolean
    IF_KPHe_Auto_Toggle
      data DE_KPHe_Auto_Toggle: type=boolean
    IF_KPHe_Funktion_ECO_Zone
      data DE_KPHe_Funktion_ECO_Zone: type=uint8
    IF_KPH_Lautsprecher
      data DE_KPH_Lautsprecher: type=uint8
    IF_KPH_Neigungssensor
      data DE_KPH_Neigungssensor: type=uint8
    IF_KPHe_Radio_Frequenz
      data DE_KPHe_Radio_Frequenz: type=uint8
    IF_KPHe_QBit_Steigung
      data DE_KPHe_QBit_Steigung: type=boolean
    IF_KPHe_Fzg_Steigung
      data DE_KPHe_Fzg_Steigung: type=uint8
    IF_ACT102f_Uebertemperatur
      data DE_ACT102f_Uebertemperatur: type=uint8
    IF_ACT104a_Notlaufposition
      data DE_ACT104a_Notlaufposition: type=uint8
    IF_ACT105a_Uebertemperatur
      data DE_ACT105a_Uebertemperatur: type=uint8
    IF_ACT104a_Adresse_Aktuator
      data DE_ACT104a_Adresse_Aktuator: type=uint8
    IF_ACT104a_Versorgungsspannung
      data DE_ACT104a_Versorgungsspannung: type=uint8
    IF_ACT109a_Adresse_Aktuator
      data DE_ACT109a_Adresse_Aktuator: type=uint8
    IF_ACT104a_Notlauf_aufgetreten
      data DE_ACT104a_Notlauf_aufgetreten: type=uint8
    IF_ACT102f_Blockierung_aufgetreten
      data DE_ACT102f_Blockierung_aufgetreten: type=uint8
    IF_ACT105a_Ist_Position_Aktuator
      data DE_ACT105a_Ist_Position_Aktuator: type=uint16
    IF_ACT106a_Selbsthaltemoment
      data DE_ACT106a_Selbsthaltemoment: type=uint8
    IF_ACT106a_Adresse_Aktuator
      data DE_ACT106a_Adresse_Aktuator: type=uint8
    IF_ACT102f_Ist_Position_Aktuator
      data DE_ACT102f_Ist_Position_Aktuator: type=uint16
    IF_ACT102f_Sonderfunktionen
      data DE_ACT102f_Sonderfunktionen: type=uint8
    IF_ACT102f_Verfahrrichtung
      data DE_ACT102f_Verfahrrichtung: type=uint8
    IF_ACT104a_Sonderfunktionen
      data DE_ACT104a_Sonderfunktionen: type=uint8
    IF_ACT104a_Verfahrrichtung
      data DE_ACT104a_Verfahrrichtung: type=uint8
    IF_ACT106a_Geschwindigkeitsstatus
      data DE_ACT106a_Geschwindigkeitsstatus: type=uint8
    IF_ACT102f_Versorgungsspannung
      data DE_ACT102f_Versorgungsspannung: type=uint8
    IF_ACT102f_Spulenbestromung
      data DE_ACT102f_Spulenbestromung: type=uint8
    IF_ACT105a_Versorgungsspannung
      data DE_ACT105a_Versorgungsspannung: type=uint8
    IF_ACT104a_Notlauffreigabe
      data DE_ACT104a_Notlauffreigabe: type=uint8
    IF_ACT106a_Blockierung_aufgetreten
      data DE_ACT106a_Blockierung_aufgetreten: type=uint8
    IF_ACT109a_Notlauffreigabe
      data DE_ACT109a_Notlauffreigabe: type=uint8
    IF_ACT105a_Variante
      data DE_ACT105a_Variante: type=uint8
    IF_ACT105a_Drehrichtung
      data DE_ACT105a_Drehrichtung: type=uint8
    IF_ACT106a_Positionsvorgabe_Status
      data DE_ACT106a_Positionsvorgabe_Status: type=uint8
    IF_ACT106a_Drehrichtung
      data DE_ACT106a_Drehrichtung: type=uint8
    IF_ACT104a_Variante
      data DE_ACT104a_Variante: type=uint8
    IF_ACT102f_Geschwindigkeitsstatus
      data DE_ACT102f_Geschwindigkeitsstatus: type=uint8
    IF_ACT109a_Stopmodus
      data DE_ACT109a_Stopmodus: type=uint8
    IF_ACT104a_Selbsthaltemoment
      data DE_ACT104a_Selbsthaltemoment: type=uint8
    IF_ACT104a_Stopmodus
      data DE_ACT104a_Stopmodus: type=uint8
    IF_ACT109a_Verfahrrichtung
      data DE_ACT109a_Verfahrrichtung: type=uint8
    IF_ACT104a_Reset
      data DE_ACT104a_Reset: type=uint8
    IF_ACT104a_Spulenbestromung
      data DE_ACT104a_Spulenbestromung: type=uint8
    IF_ACT106a_Reset
      data DE_ACT106a_Reset: type=uint8
    IF_ACT105a_Geschwindigkeitsstatus
      data DE_ACT105a_Geschwindigkeitsstatus: type=uint8
    IF_ACT104a_Drehrichtung
      data DE_ACT104a_Drehrichtung: type=uint8
    IF_ACT109a_Geschwindigkeitsstatus
      data DE_ACT109a_Geschwindigkeitsstatus: type=uint8
    IF_ACT109a_Notlauf_aufgetreten
      data DE_ACT109a_Notlauf_aufgetreten: type=uint8
    IF_ACT105a_Notlauf_aufgetreten
      data DE_ACT105a_Notlauf_aufgetreten: type=uint8
    IF_ACT106a_Versorgungsspannung
      data DE_ACT106a_Versorgungsspannung: type=uint8
    IF_ACT105a_Blockierung_aufgetreten
      data DE_ACT105a_Blockierung_aufgetreten: type=uint8
    IF_ACT106a_Ist_Position_Aktuator
      data DE_ACT106a_Ist_Position_Aktuator: type=uint16
    IF_ACT105a_Spulenbestromung
      data DE_ACT105a_Spulenbestromung: type=uint8
    IF_ACT102f_Adresse_Aktuator
      data DE_ACT102f_Adresse_Aktuator: type=uint8
    IF_ACT106a_Uebertemperatur
      data DE_ACT106a_Uebertemperatur: type=uint8
    IF_ACT105a_Notlauffreigabe
      data DE_ACT105a_Notlauffreigabe: type=uint8
    IF_ACT106a_Notlauffreigabe
      data DE_ACT106a_Notlauffreigabe: type=uint8
    IF_ACT106a_Variante
      data DE_ACT106a_Variante: type=uint8
    IF_ACT109a_Versorgungsspannung
      data DE_ACT109a_Versorgungsspannung: type=uint8
    IF_ACT105a_Positionsvorgabe_Status
      data DE_ACT105a_Positionsvorgabe_Status: type=uint8
    IF_ACT106a_Notlauf_aufgetreten
      data DE_ACT106a_Notlauf_aufgetreten: type=uint8
    IF_ACT102f_Selbsthaltemoment
      data DE_ACT102f_Selbsthaltemoment: type=uint8
    IF_ACT105a_Stopmodus
      data DE_ACT105a_Stopmodus: type=uint8
    IF_ACT105a_Selbsthaltemoment
      data DE_ACT105a_Selbsthaltemoment: type=uint8
    IF_ACT104a_Geschwindigkeitsstatus
      data DE_ACT104a_Geschwindigkeitsstatus: type=uint8
    IF_ACT105a_Adresse_Aktuator
      data DE_ACT105a_Adresse_Aktuator: type=uint8
    IF_ACT109a_Spulenbestromung
      data DE_ACT109a_Spulenbestromung: type=uint8
    IF_ACT106a_Notlaufposition
      data DE_ACT106a_Notlaufposition: type=uint8
    IF_ACT102f_Drehrichtung
      data DE_ACT102f_Drehrichtung: type=uint8
    IF_ACT104a_Positionsvorgabe_Status
      data DE_ACT104a_Positionsvorgabe_Status: type=uint8
    IF_ACT102f_Positionsvorgabe_Status
      data DE_ACT102f_Positionsvorgabe_Status: type=uint8
    IF_ACT109a_Notlaufposition
      data DE_ACT109a_Notlaufposition: type=uint8
    IF_ACT102f_Stopmodus
      data DE_ACT102f_Stopmodus: type=uint8
    IF_ACT104a_Blockierung_aufgetreten
      data DE_ACT104a_Blockierung_aufgetreten: type=uint8
    IF_ACT109a_Blockierung_aufgetreten
      data DE_ACT109a_Blockierung_aufgetreten: type=uint8
    IF_ACT109a_Uebertemperatur
      data DE_ACT109a_Uebertemperatur: type=uint8
    IF_ACT102f_Notlauffreigabe
      data DE_ACT102f_Notlauffreigabe: type=uint8
    IF_ACT109a_Drehrichtung
      data DE_ACT109a_Drehrichtung: type=uint8
    IF_ACT109a_Ist_Position_Aktuator
      data DE_ACT109a_Ist_Position_Aktuator: type=uint16
    IF_ACT104a_Uebertemperatur
      data DE_ACT104a_Uebertemperatur: type=uint8
    IF_ACT102f_Reset
      data DE_ACT102f_Reset: type=uint8
    IF_ACT106a_Stopmodus
      data DE_ACT106a_Stopmodus: type=uint8
    IF_ACT106a_Sonderfunktionen
      data DE_ACT106a_Sonderfunktionen: type=uint8
    IF_ACT102f_Variante
      data DE_ACT102f_Variante: type=uint8
    IF_ACT105a_Sonderfunktionen
      data DE_ACT105a_Sonderfunktionen: type=uint8
    IF_ACT102f_Notlauf_aufgetreten
      data DE_ACT102f_Notlauf_aufgetreten: type=uint8
    IF_ACT105a_Notlaufposition
      data DE_ACT105a_Notlaufposition: type=uint8
    IF_ACT109a_Selbsthaltemoment
      data DE_ACT109a_Selbsthaltemoment: type=uint8
    IF_ACT109a_Sonderfunktionen
      data DE_ACT109a_Sonderfunktionen: type=uint8
    IF_ACT105a_Reset
      data DE_ACT105a_Reset: type=uint8
    IF_ACT109a_Reset
      data DE_ACT109a_Reset: type=uint8
    IF_ACT106a_Spulenbestromung
      data DE_ACT106a_Spulenbestromung: type=uint8
    IF_ACT106a_Verfahrrichtung
      data DE_ACT106a_Verfahrrichtung: type=uint8
    IF_ACT109a_Positionsvorgabe_Status
      data DE_ACT109a_Positionsvorgabe_Status: type=uint8
    IF_ACT102f_Notlaufposition
      data DE_ACT102f_Notlaufposition: type=uint8
    IF_ACT105a_Verfahrrichtung
      data DE_ACT105a_Verfahrrichtung: type=uint8
    IF_ACT109a_Variante
      data DE_ACT109a_Variante: type=uint8
    IF_ACT104a_Ist_Position_Aktuator
      data DE_ACT104a_Ist_Position_Aktuator: type=uint16
    IF_STRG105a_Geschwindigkeitsvorgabe
      data DE_STRG105a_Geschwindigkeitsvorgabe: type=uint8
    IF_STRG106a_Freig_Blockiererkennung
      data DE_STRG106a_Freig_Blockiererkennung: type=uint8
    IF_STRG104a_PrgDaten_speichern
      data DE_STRG104a_PrgDaten_speichern: type=uint8
    IF_STRG104a_Adresse
      data DE_STRG104a_Adresse: type=uint8
    IF_STRG104a_Freig_Blockiererkennung
      data DE_STRG104a_Freig_Blockiererkennung: type=uint8
    IF_STRG109a_Spulenhaltebestromung
      data DE_STRG109a_Spulenhaltebestromung: type=uint8
    IF_STRG106a_Notlauffreigabe
      data DE_STRG106a_Notlauffreigabe: type=uint8
    IF_STRG102f_Start_Position
      data DE_STRG102f_Start_Position: type=uint16
    IF_STRG105a_Freig_Blockiererkennung
      data DE_STRG105a_Freig_Blockiererkennung: type=uint8
    IF_STRG106a_Geschwindigkeitsvorgabe
      data DE_STRG106a_Geschwindigkeitsvorgabe: type=uint8
    IF_STRG104a_Drehrichtung
      data DE_STRG104a_Drehrichtung: type=uint8
    IF_STRG104a_Soll_Position
      data DE_STRG104a_Soll_Position: type=uint16
    IF_STRG104a_Notlauffreigabe
      data DE_STRG104a_Notlauffreigabe: type=uint8
    IF_STRG109a_Adresse
      data DE_STRG109a_Adresse: type=uint8
    IF_STRG102f_Drehrichtung
      data DE_STRG102f_Drehrichtung: type=uint8
    IF_STRG109a_Stopmodus
      data DE_STRG109a_Stopmodus: type=uint8
    IF_STRG106a_Start_Position
      data DE_STRG106a_Start_Position: type=uint16
    IF_STRG109a_Clear_Event_Flags
      data DE_STRG109a_Clear_Event_Flags: type=uint8
    IF_STRG109a_Freig_Blockiererkennung
      data DE_STRG109a_Freig_Blockiererkennung: type=uint8
    IF_STRG109a_PrgDaten_speichern
      data DE_STRG109a_PrgDaten_speichern: type=uint8
    IF_STRG109a_Notlaufposition
      data DE_STRG109a_Notlaufposition: type=uint8
    IF_STRG105a_Select_Positionsvorgabe
      data DE_STRG105a_Select_Positionsvorgabe: type=uint8
    IF_STRG104a_Spulenhaltebestromung
      data DE_STRG104a_Spulenhaltebestromung: type=uint8
    IF_STRG106a_PrgDaten_speichern
      data DE_STRG106a_PrgDaten_speichern: type=uint8
    IF_STRG109a_Start_Position
      data DE_STRG109a_Start_Position: type=uint16
    IF_STRG106a_Select_Positionsvorgabe
      data DE_STRG106a_Select_Positionsvorgabe: type=uint8
    IF_STRG102f_Notlauffreigabe
      data DE_STRG102f_Notlauffreigabe: type=uint8
    IF_STRG106a_Notlaufposition
      data DE_STRG106a_Notlaufposition: type=uint8
    IF_STRG105a_Soll_Position
      data DE_STRG105a_Soll_Position: type=uint16
    IF_STRG105a_Drehrichtung
      data DE_STRG105a_Drehrichtung: type=uint8
    IF_STRG109a_Drehrichtung
      data DE_STRG109a_Drehrichtung: type=uint8
    IF_STRG105a_Spulenhaltebestromung
      data DE_STRG105a_Spulenhaltebestromung: type=uint8
    IF_STRG106a_Soll_Position
      data DE_STRG106a_Soll_Position: type=uint16
    IF_STRG105a_Stopmodus
      data DE_STRG105a_Stopmodus: type=uint8
    IF_STRG109a_Geschwindigkeitsvorgabe
      data DE_STRG109a_Geschwindigkeitsvorgabe: type=uint8
    IF_STRG104a_Start_Position
      data DE_STRG104a_Start_Position: type=uint16
    IF_STRG102f_Adresse
      data DE_STRG102f_Adresse: type=uint8
    IF_STRG102f_Freig_Blockiererkennung
      data DE_STRG102f_Freig_Blockiererkennung: type=uint8
    IF_STRG104a_Stopmodus
      data DE_STRG104a_Stopmodus: type=uint8
    IF_STRG102f_Stopmodus
      data DE_STRG102f_Stopmodus: type=uint8
    IF_STRG106a_Stopmodus
      data DE_STRG106a_Stopmodus: type=uint8
    IF_STRG106a_Adresse
      data DE_STRG106a_Adresse: type=uint8
    IF_STRG105a_Adresse
      data DE_STRG105a_Adresse: type=uint8
    IF_STRG105a_Notlaufposition
      data DE_STRG105a_Notlaufposition: type=uint8
    IF_STRG102f_PrgDaten_speichern
      data DE_STRG102f_PrgDaten_speichern: type=uint8
    IF_STRG106a_Spulenhaltebestromung
      data DE_STRG106a_Spulenhaltebestromung: type=uint8
    IF_STRG104a_Select_Positionsvorgabe
      data DE_STRG104a_Select_Positionsvorgabe: type=uint8
    IF_STRG104a_Notlaufposition
      data DE_STRG104a_Notlaufposition: type=uint8
    IF_STRG102f_Notlaufposition
      data DE_STRG102f_Notlaufposition: type=uint8
    IF_STRG102f_Clear_Event_Flags
      data DE_STRG102f_Clear_Event_Flags: type=uint8
    IF_STRG106a_Drehrichtung
      data DE_STRG106a_Drehrichtung: type=uint8
    IF_STRG104a_Clear_Event_Flags
      data DE_STRG104a_Clear_Event_Flags: type=uint8
    IF_STRG105a_Notlauffreigabe
      data DE_STRG105a_Notlauffreigabe: type=uint8
    IF_STRG105a_PrgDaten_speichern
      data DE_STRG105a_PrgDaten_speichern: type=uint8
    IF_STRG109a_Soll_Position
      data DE_STRG109a_Soll_Position: type=uint16
    IF_STRG106a_Clear_Event_Flags
      data DE_STRG106a_Clear_Event_Flags: type=uint8
    IF_STRG102f_Soll_Position
      data DE_STRG102f_Soll_Position: type=uint16
    IF_STRG109a_Select_Positionsvorgabe
      data DE_STRG109a_Select_Positionsvorgabe: type=uint8
    IF_STRG102f_Geschwindigkeitsvorgabe
      data DE_STRG102f_Geschwindigkeitsvorgabe: type=uint8
    IF_STRG104a_Geschwindigkeitsvorgabe
      data DE_STRG104a_Geschwindigkeitsvorgabe: type=uint8
    IF_STRG102f_Select_Positionsvorgabe
      data DE_STRG102f_Select_Positionsvorgabe: type=uint8
    IF_STRG105a_Clear_Event_Flags
      data DE_STRG105a_Clear_Event_Flags: type=uint8
    IF_STRG105a_Start_Position
      data DE_STRG105a_Start_Position: type=uint16
    IF_STRG109a_Notlauffreigabe
      data DE_STRG109a_Notlauffreigabe: type=uint8
    IF_STRG102f_Spulenhaltebestromung
      data DE_STRG102f_Spulenhaltebestromung: type=uint8
    IF_ACT109a_el_Defekt
      data DE_ACT109a_el_Defekt: type=uint8
    IF_ACT106a_el_Defekt
      data DE_ACT106a_el_Defekt: type=uint8
    IF_ACT102f_el_Defekt
      data DE_ACT102f_el_Defekt: type=uint8
    IF_ACT105a_el_Defekt
      data DE_ACT105a_el_Defekt: type=uint8
    IF_ACT104a_el_Defekt
      data DE_ACT104a_el_Defekt: type=uint8
    IF_KL_KST_KL_15
      data DE_KL_KST_KL_15: type=boolean
    IF_KL_DI_KL_58xd
      data DE_KL_DI_KL_58xd: type=uint8
    IF_KL_DI_KL_58xs
      data DE_KL_DI_KL_58xs: type=uint8
    IF_STRG100a_Freig_Blockiererkennung
      data DE_STRG100a_Freig_Blockiererkennung: type=uint8
    IF_STRG100f_Geschwindigkeitsvorgabe
      data DE_STRG100f_Geschwindigkeitsvorgabe: type=uint8
    IF_STRG100a_Notlaufposition
      data DE_STRG100a_Notlaufposition: type=uint8
    IF_STRG100a_PrgDaten_speichern
      data DE_STRG100a_PrgDaten_speichern: type=uint8
    IF_STRG100a_Start_Position
      data DE_STRG100a_Start_Position: type=uint16
    IF_STRG100f_Soll_Position
      data DE_STRG100f_Soll_Position: type=uint16
    IF_STRG100f_Notlauffreigabe
      data DE_STRG100f_Notlauffreigabe: type=uint8
    IF_STRG100f_Select_Positionsvorgabe
      data DE_STRG100f_Select_Positionsvorgabe: type=uint8
    IF_STRG100a_Notlauffreigabe
      data DE_STRG100a_Notlauffreigabe: type=uint8
    IF_STRG100f_Adresse
      data DE_STRG100f_Adresse: type=uint8
    IF_STRG100f_Start_Position
      data DE_STRG100f_Start_Position: type=uint16
    IF_STRG100f_Clear_Event_Flags
      data DE_STRG100f_Clear_Event_Flags: type=uint8
    IF_STRG100a_Select_Positionsvorgabe
      data DE_STRG100a_Select_Positionsvorgabe: type=uint8
    IF_STRG100a_Clear_Event_Flags
      data DE_STRG100a_Clear_Event_Flags: type=uint8
    IF_STRG100a_Soll_Position
      data DE_STRG100a_Soll_Position: type=uint16
    IF_STRG100f_Stopmodus
      data DE_STRG100f_Stopmodus: type=uint8
    IF_STRG100f_Spulenhaltebestromung
      data DE_STRG100f_Spulenhaltebestromung: type=uint8
    IF_STRG100a_Stopmodus
      data DE_STRG100a_Stopmodus: type=uint8
    IF_STRG100a_Adresse
      data DE_STRG100a_Adresse: type=uint8
    IF_STRG100a_Spulenhaltebestromung
      data DE_STRG100a_Spulenhaltebestromung: type=uint8
    IF_STRG100a_Drehrichtung
      data DE_STRG100a_Drehrichtung: type=uint8
    IF_STRG100f_Notlaufposition
      data DE_STRG100f_Notlaufposition: type=uint8
    IF_STRG100f_Freig_Blockiererkennung
      data DE_STRG100f_Freig_Blockiererkennung: type=uint8
    IF_STRG100f_Drehrichtung
      data DE_STRG100f_Drehrichtung: type=uint8
    IF_STRG100a_Geschwindigkeitsvorgabe
      data DE_STRG100a_Geschwindigkeitsvorgabe: type=uint8
    IF_STRG100f_PrgDaten_speichern
      data DE_STRG100f_PrgDaten_speichern: type=uint8
    IF_KPHe_Funktion_Defrost
      data DE_KPHe_Funktion_Defrost: type=boolean
    IF_KPH_ECO_links
      data DE_KPH_ECO_links: type=boolean
    IF_KPH_ECO_rechts
      data DE_KPH_ECO_rechts: type=boolean
    IF_Zone_VR_SNI_10
      data DE_Zone_VR_SNI_10: type=uint16
    IF_ClSensUIF_st_State_S
      data DE_ClSensUIF_st_State_S: type=uint8
    IF_ClSensUIF_T_FilUIF_S
      data DE_ClSensUIF_T_FilUIF_S: type=uint16
    IF_ClSensUIF_T_ValUIF_S
      data DE_ClSensUIF_T_ValUIF_S: type=uint16
    IF_ClSensTemp_T_TempKGFrnt_S
      data DE_ClSensTemp_T_TempKGFrnt_S: type=uint16
    IF_ClActFan_st_BlowerSt_S
      data DE_ClActFan_st_BlowerSt_S: type=uint8
    IF_ClActFan_perc_BlowerCurVal_S
      data DE_ClActFan_perc_BlowerCurVal_S: type=uint8
    IF_ClCcpRear_no_SetDfrst_S
      data DE_ClCcpRear_no_SetDfrst_S: type=uint8
    IF_ClCcpRear_no_TarDfrst_S
      data DE_ClCcpRear_no_TarDfrst_S: type=uint8
    IF_ClCcpRear_T_TarTempLe
      data DE_ClCcpRear_T_TarTempLe: type=uint8
    IF_ClCcpRear_T_TarTempRi
      data DE_ClCcpRear_T_TarTempRi: type=uint8
    IF_ClAct_st_FlapDfrst_S
      data DE_ClAct_st_FlapDfrst_S: type=uint8
    IF_ClAct_perc_FlapDfrstCurVal_S
      data DE_ClAct_perc_FlapDfrstCurVal_S: type=uint8
    IF_ClAct_st_FlapTempFrntLe_S
      data DE_ClAct_st_FlapTempFrntLe_S: type=uint8
    IF_ClAct_st_FlapTempFrntRi_S
      data DE_ClAct_st_FlapTempFrntRi_S: type=uint8
    IF_ClAct_st_FlapTempRearLe_S
      data DE_ClAct_st_FlapTempRearLe_S: type=uint8
    IF_ClHmi_SetBit1_S
      data DE_ClHmi_SetBit1_S: type=uint16
    IF_ClAct_perc_FlapTFrntLeCurVal
      data DE_ClAct_perc_FlapTFrntLeCurVal: type=uint8
    IF_ClAct_perc_FlapTFrntRiCurVal
      data DE_ClAct_perc_FlapTFrntRiCurVal: type=uint8
    IF_ClAct_perc_FlapTRearLeCurVal
      data DE_ClAct_perc_FlapTRearLeCurVal: type=uint8
    IF_ClAct_st_FlapTRearRiDfrst
      data DE_ClAct_st_FlapTRearRiDfrst: type=uint8
    IF_ClAct_perc_FlapTRearRiCurVal
      data DE_ClAct_perc_FlapTRearRiCurVal: type=uint8
    IF_ClHmi_SetBit2_S
      data DE_ClHmi_SetBit2_S: type=uint16
    IF_ClActFan_perc_BlowerTarVal_S
      data DE_ClActFan_perc_BlowerTarVal_S: type=uint8
    IF_ClHmi_st_StDfrst_S
      data DE_ClHmi_st_StDfrst_S: type=uint8
    IF_ClHmi_T_CurTempFrntLe_S
      data DE_ClHmi_T_CurTempFrntLe_S: type=uint8
    IF_ClHmi_T_CurTempFrntRi_S
      data DE_ClHmi_T_CurTempFrntRi_S: type=uint8
    IF_ClHmi_T_CurTempRearLe_S
      data DE_ClHmi_T_CurTempRearLe_S: type=uint8
    IF_ClHmi_T_CurTempRearRi_S
      data DE_ClHmi_T_CurTempRearRi_S: type=uint8
    IF_ClStm_OpState
      data DE_ClStm_OpState: type=uint8
    IF_ClAct_perc_FlapDfrstTarVal
      data DE_ClAct_perc_FlapDfrstTarVal: type=uint8
    IF_ClAct_perc_FlapTFrntLeTarVal
      data DE_ClAct_perc_FlapTFrntLeTarVal: type=uint8
    IF_ClAct_perc_FlapTFrntRiTarVal
      data DE_ClAct_perc_FlapTFrntRiTarVal: type=uint8
    IF_ClAct_perc_FlapTRearLeTarVal
      data DE_ClAct_perc_FlapTRearLeTarVal: type=uint8
    IF_ClAct_perc_FlapTRearRiTarVal
      data DE_ClAct_perc_FlapTRearRiTarVal: type=uint8
    IF_ClSens_SetBit1_S
      data DE_ClSens_SetBit1_S: type=uint16
    IF_ClSens_SetBit2_S
      data DE_ClSens_SetBit2_S: type=uint16
    IF_TME_T_OutsideAirTemp_raw
      data DE_TME_T_OutsideAirTemp_raw: type=uint16
package /ComponentTypes
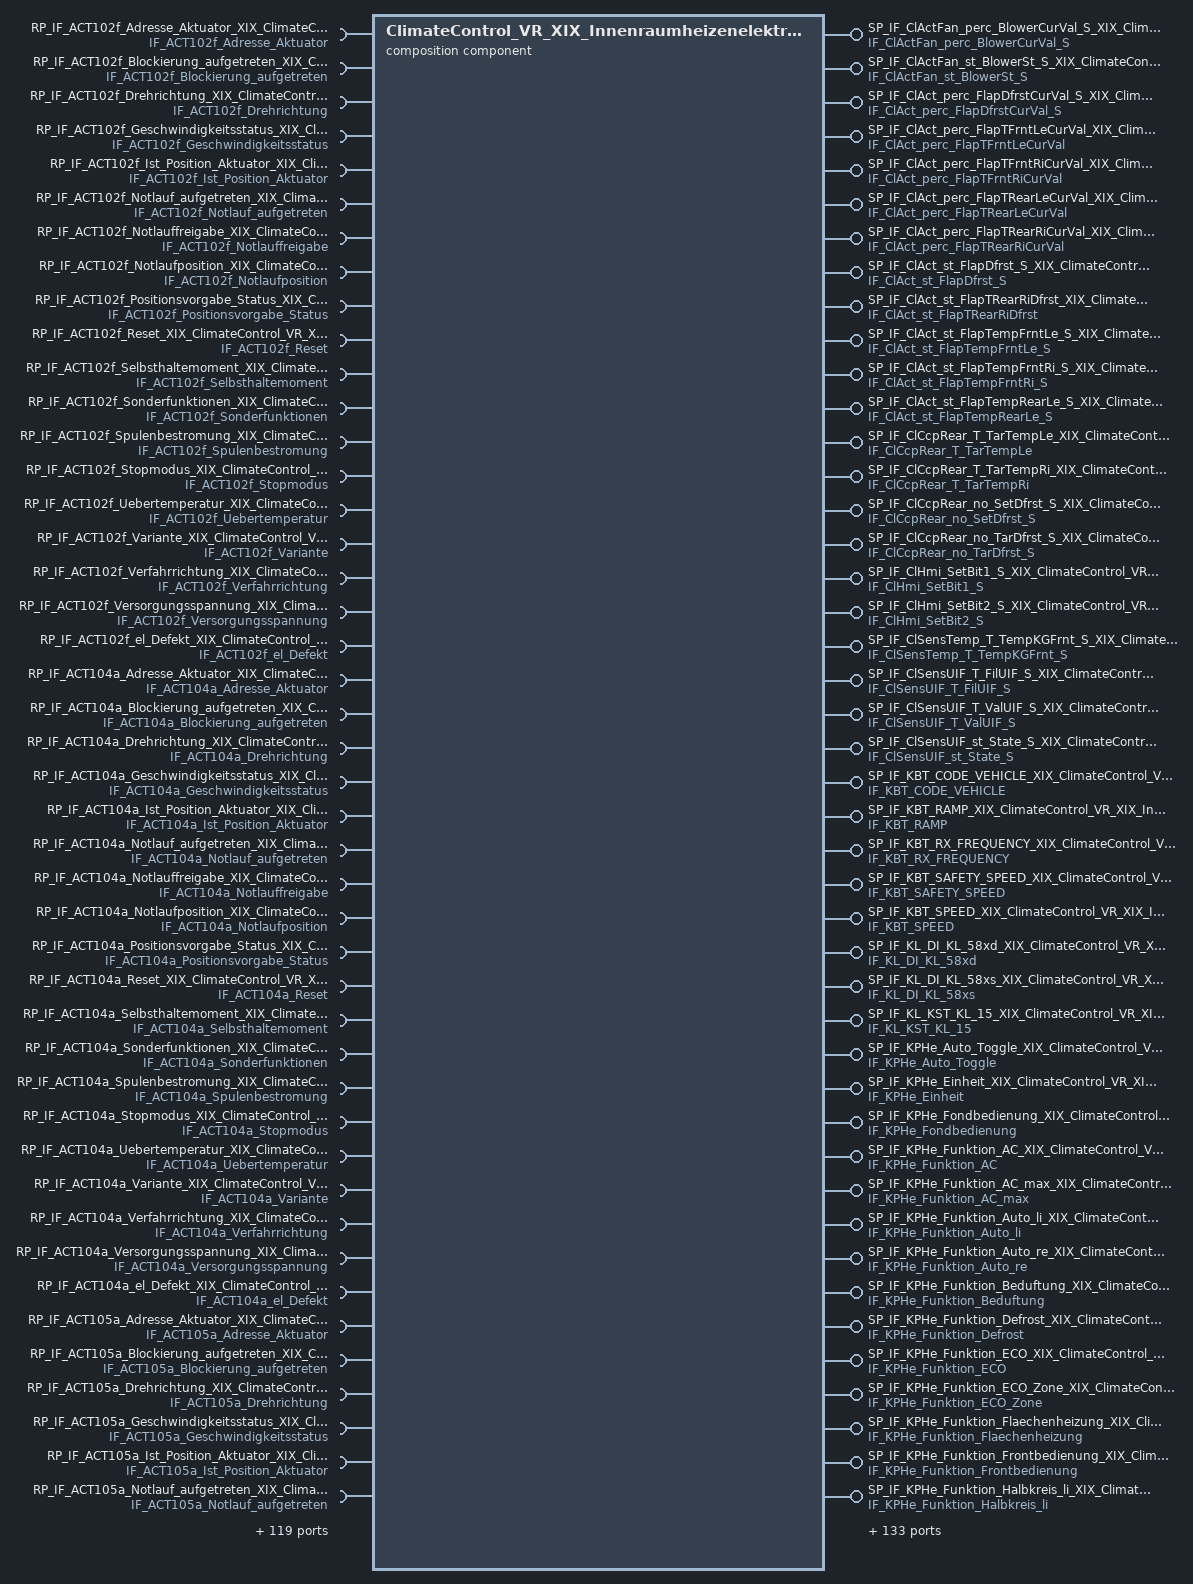
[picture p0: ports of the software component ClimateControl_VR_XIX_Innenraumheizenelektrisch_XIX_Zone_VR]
  composition sw component type ClimateControl_VR_XIX_Innenraumheizenelektrisch_XIX_Zone_VR
    177 x provide port:
      SP_IF_ClActFan_perc_BlowerCurVal_S_XIX_ClimateControl_VR_XIX_Innenraumheizenelektrisch_XIX_Zone_VR: provided-interface=IF_ClActFan_perc_BlowerCurVal_S
      SP_IF_ClActFan_st_BlowerSt_S_XIX_ClimateControl_VR_XIX_Innenraumheizenelektrisch_XIX_Zone_VR: provided-interface=IF_ClActFan_st_BlowerSt_S
      SP_IF_ClAct_perc_FlapDfrstCurVal_S_XIX_ClimateControl_VR_XIX_Innenraumheizenelektrisch_XIX_Zone_VR: provided-interface=IF_ClAct_perc_FlapDfrstCurVal_S
      SP_IF_ClAct_perc_FlapTFrntLeCurVal_XIX_ClimateControl_VR_XIX_Innenraumheizenelektrisch_XIX_Zone_VR: provided-interface=IF_ClAct_perc_FlapTFrntLeCurVal
      SP_IF_ClAct_perc_FlapTFrntRiCurVal_XIX_ClimateControl_VR_XIX_Innenraumheizenelektrisch_XIX_Zone_VR: provided-interface=IF_ClAct_perc_FlapTFrntRiCurVal
      SP_IF_ClAct_perc_FlapTRearLeCurVal_XIX_ClimateControl_VR_XIX_Innenraumheizenelektrisch_XIX_Zone_VR: provided-interface=IF_ClAct_perc_FlapTRearLeCurVal
      SP_IF_ClAct_perc_FlapTRearRiCurVal_XIX_ClimateControl_VR_XIX_Innenraumheizenelektrisch_XIX_Zone_VR: provided-interface=IF_ClAct_perc_FlapTRearRiCurVal
      SP_IF_ClAct_st_FlapDfrst_S_XIX_ClimateControl_VR_XIX_Innenraumheizenelektrisch_XIX_Zone_VR: provided-interface=IF_ClAct_st_FlapDfrst_S
      SP_IF_ClAct_st_FlapTRearRiDfrst_XIX_ClimateControl_VR_XIX_Innenraumheizenelektrisch_XIX_Zone_VR: provided-interface=IF_ClAct_st_FlapTRearRiDfrst
      SP_IF_ClAct_st_FlapTempFrntLe_S_XIX_ClimateControl_VR_XIX_Innenraumheizenelektrisch_XIX_Zone_VR: provided-interface=IF_ClAct_st_FlapTempFrntLe_S
      SP_IF_ClAct_st_FlapTempFrntRi_S_XIX_ClimateControl_VR_XIX_Innenraumheizenelektrisch_XIX_Zone_VR: provided-interface=IF_ClAct_st_FlapTempFrntRi_S
      SP_IF_ClAct_st_FlapTempRearLe_S_XIX_ClimateControl_VR_XIX_Innenraumheizenelektrisch_XIX_Zone_VR: provided-interface=IF_ClAct_st_FlapTempRearLe_S
      SP_IF_ClCcpRear_T_TarTempLe_XIX_ClimateControl_VR_XIX_Innenraumheizenelektrisch_XIX_Zone_VR: provided-interface=IF_ClCcpRear_T_TarTempLe
      SP_IF_ClCcpRear_T_TarTempRi_XIX_ClimateControl_VR_XIX_Innenraumheizenelektrisch_XIX_Zone_VR: provided-interface=IF_ClCcpRear_T_TarTempRi
      SP_IF_ClCcpRear_no_SetDfrst_S_XIX_ClimateControl_VR_XIX_Innenraumheizenelektrisch_XIX_Zone_VR: provided-interface=IF_ClCcpRear_no_SetDfrst_S
      SP_IF_ClCcpRear_no_TarDfrst_S_XIX_ClimateControl_VR_XIX_Innenraumheizenelektrisch_XIX_Zone_VR: provided-interface=IF_ClCcpRear_no_TarDfrst_S
      SP_IF_ClHmi_SetBit1_S_XIX_ClimateControl_VR_XIX_Innenraumheizenelektrisch_XIX_Zone_VR: provided-interface=IF_ClHmi_SetBit1_S
      SP_IF_ClHmi_SetBit2_S_XIX_ClimateControl_VR_XIX_Innenraumheizenelektrisch_XIX_Zone_VR: provided-interface=IF_ClHmi_SetBit2_S
      SP_IF_ClSensTemp_T_TempKGFrnt_S_XIX_ClimateControl_VR_XIX_Innenraumheizenelektrisch_XIX_Zone_VR: provided-interface=IF_ClSensTemp_T_TempKGFrnt_S
      SP_IF_ClSensUIF_T_FilUIF_S_XIX_ClimateControl_VR_XIX_Innenraumheizenelektrisch_XIX_Zone_VR: provided-interface=IF_ClSensUIF_T_FilUIF_S
      SP_IF_ClSensUIF_T_ValUIF_S_XIX_ClimateControl_VR_XIX_Innenraumheizenelektrisch_XIX_Zone_VR: provided-interface=IF_ClSensUIF_T_ValUIF_S
      SP_IF_ClSensUIF_st_State_S_XIX_ClimateControl_VR_XIX_Innenraumheizenelektrisch_XIX_Zone_VR: provided-interface=IF_ClSensUIF_st_State_S
      SP_IF_KBT_CODE_VEHICLE_XIX_ClimateControl_VR_XIX_Innenraumheizenelektrisch_XIX_Zone_VR: provided-interface=IF_KBT_CODE_VEHICLE
      SP_IF_KBT_RAMP_XIX_ClimateControl_VR_XIX_Innenraumheizenelektrisch_XIX_Zone_VR: provided-interface=IF_KBT_RAMP
      SP_IF_KBT_RX_FREQUENCY_XIX_ClimateControl_VR_XIX_Innenraumheizenelektrisch_XIX_Zone_VR: provided-interface=IF_KBT_RX_FREQUENCY
      SP_IF_KBT_SAFETY_SPEED_XIX_ClimateControl_VR_XIX_Innenraumheizenelektrisch_XIX_Zone_VR: provided-interface=IF_KBT_SAFETY_SPEED
      SP_IF_KBT_SPEED_XIX_ClimateControl_VR_XIX_Innenraumheizenelektrisch_XIX_Zone_VR: provided-interface=IF_KBT_SPEED
      SP_IF_KL_DI_KL_58xd_XIX_ClimateControl_VR_XIX_Innenraumheizenelektrisch_XIX_Zone_VR: provided-interface=IF_KL_DI_KL_58xd
      SP_IF_KL_DI_KL_58xs_XIX_ClimateControl_VR_XIX_Innenraumheizenelektrisch_XIX_Zone_VR: provided-interface=IF_KL_DI_KL_58xs
      SP_IF_KL_KST_KL_15_XIX_ClimateControl_VR_XIX_Innenraumheizenelektrisch_XIX_Zone_VR: provided-interface=IF_KL_KST_KL_15
      SP_IF_KPHe_Auto_Toggle_XIX_ClimateControl_VR_XIX_Innenraumheizenelektrisch_XIX_Zone_VR: provided-interface=IF_KPHe_Auto_Toggle
      SP_IF_KPHe_Einheit_XIX_ClimateControl_VR_XIX_Innenraumheizenelektrisch_XIX_Zone_VR: provided-interface=IF_KPHe_Einheit
      SP_IF_KPHe_Fondbedienung_XIX_ClimateControl_VR_XIX_Innenraumheizenelektrisch_XIX_Zone_VR: provided-interface=IF_KPHe_Fondbedienung
      SP_IF_KPHe_Funktion_AC_XIX_ClimateControl_VR_XIX_Innenraumheizenelektrisch_XIX_Zone_VR: provided-interface=IF_KPHe_Funktion_AC
      SP_IF_KPHe_Funktion_AC_max_XIX_ClimateControl_VR_XIX_Innenraumheizenelektrisch_XIX_Zone_VR: provided-interface=IF_KPHe_Funktion_AC_max
      SP_IF_KPHe_Funktion_Auto_li_XIX_ClimateControl_VR_XIX_Innenraumheizenelektrisch_XIX_Zone_VR: provided-interface=IF_KPHe_Funktion_Auto_li
      SP_IF_KPHe_Funktion_Auto_re_XIX_ClimateControl_VR_XIX_Innenraumheizenelektrisch_XIX_Zone_VR: provided-interface=IF_KPHe_Funktion_Auto_re
      SP_IF_KPHe_Funktion_Beduftung_XIX_ClimateControl_VR_XIX_Innenraumheizenelektrisch_XIX_Zone_VR: provided-interface=IF_KPHe_Funktion_Beduftung
      SP_IF_KPHe_Funktion_Defrost_XIX_ClimateControl_VR_XIX_Innenraumheizenelektrisch_XIX_Zone_VR: provided-interface=IF_KPHe_Funktion_Defrost
      SP_IF_KPHe_Funktion_ECO_XIX_ClimateControl_VR_XIX_Innenraumheizenelektrisch_XIX_Zone_VR: provided-interface=IF_KPHe_Funktion_ECO
      SP_IF_KPHe_Funktion_ECO_Zone_XIX_ClimateControl_VR_XIX_Innenraumheizenelektrisch_XIX_Zone_VR: provided-interface=IF_KPHe_Funktion_ECO_Zone
      SP_IF_KPHe_Funktion_Flaechenheizung_XIX_ClimateControl_VR_XIX_Innenraumheizenelektrisch_XIX_Zone_VR: provided-interface=IF_KPHe_Funktion_Flaechenheizung
      SP_IF_KPHe_Funktion_Frontbedienung_XIX_ClimateControl_VR_XIX_Innenraumheizenelektrisch_XIX_Zone_VR: provided-interface=IF_KPHe_Funktion_Frontbedienung
      SP_IF_KPHe_Funktion_Halbkreis_li_XIX_ClimateControl_VR_XIX_Innenraumheizenelektrisch_XIX_Zone_VR: provided-interface=IF_KPHe_Funktion_Halbkreis_li
      SP_IF_KPHe_Funktion_Halbkreis_re_XIX_ClimateControl_VR_XIX_Innenraumheizenelektrisch_XIX_Zone_VR: provided-interface=IF_KPHe_Funktion_Halbkreis_re
      SP_IF_KPHe_Funktion_Ionisator_XIX_ClimateControl_VR_XIX_Innenraumheizenelektrisch_XIX_Zone_VR: provided-interface=IF_KPHe_Funktion_Ionisator
      SP_IF_KPHe_Funktion_Kindersicherung_XIX_ClimateControl_VR_XIX_Innenraumheizenelektrisch_XIX_Zone_VR: provided-interface=IF_KPHe_Funktion_Kindersicherung
      SP_IF_KPHe_Funktion_Off_XIX_ClimateControl_VR_XIX_Innenraumheizenelektrisch_XIX_Zone_VR: provided-interface=IF_KPHe_Funktion_Off
      SP_IF_KPHe_Funktion_Sync_XIX_ClimateControl_VR_XIX_Innenraumheizenelektrisch_XIX_Zone_VR: provided-interface=IF_KPHe_Funktion_Sync
      SP_IF_KPHe_Funktion_Umluft_XIX_ClimateControl_VR_XIX_Innenraumheizenelektrisch_XIX_Zone_VR: provided-interface=IF_KPHe_Funktion_Umluft
      SP_IF_KPHe_Funktionsbeleuchtung_XIX_ClimateControl_VR_XIX_Innenraumheizenelektrisch_XIX_Zone_VR: provided-interface=IF_KPHe_Funktionsbeleuchtung
      SP_IF_KPHe_Fzg_Steigung_XIX_ClimateControl_VR_XIX_Innenraumheizenelektrisch_XIX_Zone_VR: provided-interface=IF_KPHe_Fzg_Steigung
      SP_IF_KPHe_Geblaese_Auto_li_XIX_ClimateControl_VR_XIX_Innenraumheizenelektrisch_XIX_Zone_VR: provided-interface=IF_KPHe_Geblaese_Auto_li
      SP_IF_KPHe_Geblaese_Auto_re_XIX_ClimateControl_VR_XIX_Innenraumheizenelektrisch_XIX_Zone_VR: provided-interface=IF_KPHe_Geblaese_Auto_re
      SP_IF_KPHe_Geblaese_Begrenzung_XIX_ClimateControl_VR_XIX_Innenraumheizenelektrisch_XIX_Zone_VR: provided-interface=IF_KPHe_Geblaese_Begrenzung
      SP_IF_KPHe_Geblaese_Stufe_li_XIX_ClimateControl_VR_XIX_Innenraumheizenelektrisch_XIX_Zone_VR: provided-interface=IF_KPHe_Geblaese_Stufe_li
      SP_IF_KPHe_Geblaese_Stufe_re_XIX_ClimateControl_VR_XIX_Innenraumheizenelektrisch_XIX_Zone_VR: provided-interface=IF_KPHe_Geblaese_Stufe_re
      SP_IF_KPHe_LCD_XIX_ClimateControl_VR_XIX_Innenraumheizenelektrisch_XIX_Zone_VR: provided-interface=IF_KPHe_LCD
      SP_IF_KPHe_Lenker_Position_XIX_ClimateControl_VR_XIX_Innenraumheizenelektrisch_XIX_Zone_VR: provided-interface=IF_KPHe_Lenker_Position
      SP_IF_KPHe_Luftverteilung_Auto_li_XIX_ClimateControl_VR_XIX_Innenraumheizenelektrisch_XIX_Zone_VR: provided-interface=IF_KPHe_Luftverteilung_Auto_li
      SP_IF_KPHe_Luftverteilung_Auto_re_XIX_ClimateControl_VR_XIX_Innenraumheizenelektrisch_XIX_Zone_VR: provided-interface=IF_KPHe_Luftverteilung_Auto_re
      SP_IF_KPHe_Luftverteilung_Mitte_li_XIX_ClimateControl_VR_XIX_Innenraumheizenelektrisch_XIX_Zone_VR: provided-interface=IF_KPHe_Luftverteilung_Mitte_li
      SP_IF_KPHe_Luftverteilung_Mitte_re_XIX_ClimateControl_VR_XIX_Innenraumheizenelektrisch_XIX_Zone_VR: provided-interface=IF_KPHe_Luftverteilung_Mitte_re
      SP_IF_KPHe_Luftverteilung_Oben_li_XIX_ClimateControl_VR_XIX_Innenraumheizenelektrisch_XIX_Zone_VR: provided-interface=IF_KPHe_Luftverteilung_Oben_li
      SP_IF_KPHe_Luftverteilung_Oben_re_XIX_ClimateControl_VR_XIX_Innenraumheizenelektrisch_XIX_Zone_VR: provided-interface=IF_KPHe_Luftverteilung_Oben_re
      SP_IF_KPHe_Luftverteilung_Unten_li_XIX_ClimateControl_VR_XIX_Innenraumheizenelektrisch_XIX_Zone_VR: provided-interface=IF_KPHe_Luftverteilung_Unten_li
      SP_IF_KPHe_Luftverteilung_Unten_re_XIX_ClimateControl_VR_XIX_Innenraumheizenelektrisch_XIX_Zone_VR: provided-interface=IF_KPHe_Luftverteilung_Unten_re
      SP_IF_KPHe_QBit_Steigung_XIX_ClimateControl_VR_XIX_Innenraumheizenelektrisch_XIX_Zone_VR: provided-interface=IF_KPHe_QBit_Steigung
      SP_IF_KPHe_Radio_Frequenz_XIX_ClimateControl_VR_XIX_Innenraumheizenelektrisch_XIX_Zone_VR: provided-interface=IF_KPHe_Radio_Frequenz
      SP_IF_KPHe_Sitzheizung_li_XIX_ClimateControl_VR_XIX_Innenraumheizenelektrisch_XIX_Zone_VR: provided-interface=IF_KPHe_Sitzheizung_li
      SP_IF_KPHe_Sitzheizung_re_XIX_ClimateControl_VR_XIX_Innenraumheizenelektrisch_XIX_Zone_VR: provided-interface=IF_KPHe_Sitzheizung_re
      SP_IF_KPHe_Sitzlueftung_li_XIX_ClimateControl_VR_XIX_Innenraumheizenelektrisch_XIX_Zone_VR: provided-interface=IF_KPHe_Sitzlueftung_li
      SP_IF_KPHe_Sitzlueftung_re_XIX_ClimateControl_VR_XIX_Innenraumheizenelektrisch_XIX_Zone_VR: provided-interface=IF_KPHe_Sitzlueftung_re
      SP_IF_KPHe_Stellgliedtest_XIX_ClimateControl_VR_XIX_Innenraumheizenelektrisch_XIX_Zone_VR: provided-interface=IF_KPHe_Stellgliedtest
      SP_IF_KPHe_Suchbeleuchtung_XIX_ClimateControl_VR_XIX_Innenraumheizenelektrisch_XIX_Zone_VR: provided-interface=IF_KPHe_Suchbeleuchtung
      SP_IF_KPHe_Symbol_Luftmenge_li_XIX_ClimateControl_VR_XIX_Innenraumheizenelektrisch_XIX_Zone_VR: provided-interface=IF_KPHe_Symbol_Luftmenge_li
      SP_IF_KPHe_Symbol_Luftmenge_re_XIX_ClimateControl_VR_XIX_Innenraumheizenelektrisch_XIX_Zone_VR: provided-interface=IF_KPHe_Symbol_Luftmenge_re
      SP_IF_KPHe_Symbol_Luftverteilung_li_XIX_ClimateControl_VR_XIX_Innenraumheizenelektrisch_XIX_Zone_VR: provided-interface=IF_KPHe_Symbol_Luftverteilung_li
      SP_IF_KPHe_Symbol_Luftverteilung_re_XIX_ClimateControl_VR_XIX_Innenraumheizenelektrisch_XIX_Zone_VR: provided-interface=IF_KPHe_Symbol_Luftverteilung_re
      SP_IF_KPHe_Symbol_Sitzheizung_li_XIX_ClimateControl_VR_XIX_Innenraumheizenelektrisch_XIX_Zone_VR: provided-interface=IF_KPHe_Symbol_Sitzheizung_li
      SP_IF_KPHe_Symbol_Sitzheizung_re_XIX_ClimateControl_VR_XIX_Innenraumheizenelektrisch_XIX_Zone_VR: provided-interface=IF_KPHe_Symbol_Sitzheizung_re
      SP_IF_KPHe_Symbol_Sitzlueftung_li_XIX_ClimateControl_VR_XIX_Innenraumheizenelektrisch_XIX_Zone_VR: provided-interface=IF_KPHe_Symbol_Sitzlueftung_li
      SP_IF_KPHe_Symbol_Sitzlueftung_re_XIX_ClimateControl_VR_XIX_Innenraumheizenelektrisch_XIX_Zone_VR: provided-interface=IF_KPHe_Symbol_Sitzlueftung_re
      SP_IF_KPHe_TFT_XIX_ClimateControl_VR_XIX_Innenraumheizenelektrisch_XIX_Zone_VR: provided-interface=IF_KPHe_TFT
      SP_IF_KPHe_Temp_li_XIX_ClimateControl_VR_XIX_Innenraumheizenelektrisch_XIX_Zone_VR: provided-interface=IF_KPHe_Temp_li
      SP_IF_KPHe_Temp_re_XIX_ClimateControl_VR_XIX_Innenraumheizenelektrisch_XIX_Zone_VR: provided-interface=IF_KPHe_Temp_re
      SP_IF_STRG100a_Adresse_XIX_ClimateControl_VR_XIX_Innenraumheizenelektrisch_XIX_Zone_VR: provided-interface=IF_STRG100a_Adresse
      SP_IF_STRG100a_Clear_Event_Flags_XIX_ClimateControl_VR_XIX_Innenraumheizenelektrisch_XIX_Zone_VR: provided-interface=IF_STRG100a_Clear_Event_Flags
      SP_IF_STRG100a_Drehrichtung_XIX_ClimateControl_VR_XIX_Innenraumheizenelektrisch_XIX_Zone_VR: provided-interface=IF_STRG100a_Drehrichtung
      SP_IF_STRG100a_Freig_Blockiererkennung_XIX_ClimateControl_VR_XIX_Innenraumheizenelektrisch_XIX_Zone_VR: provided-interface=IF_STRG100a_Freig_Blockiererkennung
      SP_IF_STRG100a_Geschwindigkeitsvorgabe_XIX_ClimateControl_VR_XIX_Innenraumheizenelektrisch_XIX_Zone_VR: provided-interface=IF_STRG100a_Geschwindigkeitsvorgabe
      SP_IF_STRG100a_Notlauffreigabe_XIX_ClimateControl_VR_XIX_Innenraumheizenelektrisch_XIX_Zone_VR: provided-interface=IF_STRG100a_Notlauffreigabe
      SP_IF_STRG100a_Notlaufposition_XIX_ClimateControl_VR_XIX_Innenraumheizenelektrisch_XIX_Zone_VR: provided-interface=IF_STRG100a_Notlaufposition
      SP_IF_STRG100a_PrgDaten_speichern_XIX_ClimateControl_VR_XIX_Innenraumheizenelektrisch_XIX_Zone_VR: provided-interface=IF_STRG100a_PrgDaten_speichern
      SP_IF_STRG100a_Select_Positionsvorgabe_XIX_ClimateControl_VR_XIX_Innenraumheizenelektrisch_XIX_Zone_VR: provided-interface=IF_STRG100a_Select_Positionsvorgabe
      SP_IF_STRG100a_Soll_Position_XIX_ClimateControl_VR_XIX_Innenraumheizenelektrisch_XIX_Zone_VR: provided-interface=IF_STRG100a_Soll_Position
      SP_IF_STRG100a_Spulenhaltebestromung_XIX_ClimateControl_VR_XIX_Innenraumheizenelektrisch_XIX_Zone_VR: provided-interface=IF_STRG100a_Spulenhaltebestromung
      SP_IF_STRG100a_Start_Position_XIX_ClimateControl_VR_XIX_Innenraumheizenelektrisch_XIX_Zone_VR: provided-interface=IF_STRG100a_Start_Position
      SP_IF_STRG100a_Stopmodus_XIX_ClimateControl_VR_XIX_Innenraumheizenelektrisch_XIX_Zone_VR: provided-interface=IF_STRG100a_Stopmodus
      SP_IF_STRG100f_Adresse_XIX_ClimateControl_VR_XIX_Innenraumheizenelektrisch_XIX_Zone_VR: provided-interface=IF_STRG100f_Adresse
      SP_IF_STRG100f_Clear_Event_Flags_XIX_ClimateControl_VR_XIX_Innenraumheizenelektrisch_XIX_Zone_VR: provided-interface=IF_STRG100f_Clear_Event_Flags
      SP_IF_STRG100f_Drehrichtung_XIX_ClimateControl_VR_XIX_Innenraumheizenelektrisch_XIX_Zone_VR: provided-interface=IF_STRG100f_Drehrichtung
      SP_IF_STRG100f_Freig_Blockiererkennung_XIX_ClimateControl_VR_XIX_Innenraumheizenelektrisch_XIX_Zone_VR: provided-interface=IF_STRG100f_Freig_Blockiererkennung
      SP_IF_STRG100f_Geschwindigkeitsvorgabe_XIX_ClimateControl_VR_XIX_Innenraumheizenelektrisch_XIX_Zone_VR: provided-interface=IF_STRG100f_Geschwindigkeitsvorgabe
      SP_IF_STRG100f_Notlauffreigabe_XIX_ClimateControl_VR_XIX_Innenraumheizenelektrisch_XIX_Zone_VR: provided-interface=IF_STRG100f_Notlauffreigabe
      SP_IF_STRG100f_Notlaufposition_XIX_ClimateControl_VR_XIX_Innenraumheizenelektrisch_XIX_Zone_VR: provided-interface=IF_STRG100f_Notlaufposition
      SP_IF_STRG100f_PrgDaten_speichern_XIX_ClimateControl_VR_XIX_Innenraumheizenelektrisch_XIX_Zone_VR: provided-interface=IF_STRG100f_PrgDaten_speichern
      SP_IF_STRG100f_Select_Positionsvorgabe_XIX_ClimateControl_VR_XIX_Innenraumheizenelektrisch_XIX_Zone_VR: provided-interface=IF_STRG100f_Select_Positionsvorgabe
      SP_IF_STRG100f_Soll_Position_XIX_ClimateControl_VR_XIX_Innenraumheizenelektrisch_XIX_Zone_VR: provided-interface=IF_STRG100f_Soll_Position
      SP_IF_STRG100f_Spulenhaltebestromung_XIX_ClimateControl_VR_XIX_Innenraumheizenelektrisch_XIX_Zone_VR: provided-interface=IF_STRG100f_Spulenhaltebestromung
      SP_IF_STRG100f_Start_Position_XIX_ClimateControl_VR_XIX_Innenraumheizenelektrisch_XIX_Zone_VR: provided-interface=IF_STRG100f_Start_Position
      SP_IF_STRG100f_Stopmodus_XIX_ClimateControl_VR_XIX_Innenraumheizenelektrisch_XIX_Zone_VR: provided-interface=IF_STRG100f_Stopmodus
      SP_IF_STRG102f_Adresse_XIX_ClimateControl_VR_XIX_Innenraumheizenelektrisch_XIX_Zone_VR: provided-interface=IF_STRG102f_Adresse
      SP_IF_STRG102f_Clear_Event_Flags_XIX_ClimateControl_VR_XIX_Innenraumheizenelektrisch_XIX_Zone_VR: provided-interface=IF_STRG102f_Clear_Event_Flags
      SP_IF_STRG102f_Drehrichtung_XIX_ClimateControl_VR_XIX_Innenraumheizenelektrisch_XIX_Zone_VR: provided-interface=IF_STRG102f_Drehrichtung
      SP_IF_STRG102f_Freig_Blockiererkennung_XIX_ClimateControl_VR_XIX_Innenraumheizenelektrisch_XIX_Zone_VR: provided-interface=IF_STRG102f_Freig_Blockiererkennung
      SP_IF_STRG102f_Geschwindigkeitsvorgabe_XIX_ClimateControl_VR_XIX_Innenraumheizenelektrisch_XIX_Zone_VR: provided-interface=IF_STRG102f_Geschwindigkeitsvorgabe
      SP_IF_STRG102f_Notlauffreigabe_XIX_ClimateControl_VR_XIX_Innenraumheizenelektrisch_XIX_Zone_VR: provided-interface=IF_STRG102f_Notlauffreigabe
      SP_IF_STRG102f_Notlaufposition_XIX_ClimateControl_VR_XIX_Innenraumheizenelektrisch_XIX_Zone_VR: provided-interface=IF_STRG102f_Notlaufposition
      SP_IF_STRG102f_PrgDaten_speichern_XIX_ClimateControl_VR_XIX_Innenraumheizenelektrisch_XIX_Zone_VR: provided-interface=IF_STRG102f_PrgDaten_speichern
      SP_IF_STRG102f_Select_Positionsvorgabe_XIX_ClimateControl_VR_XIX_Innenraumheizenelektrisch_XIX_Zone_VR: provided-interface=IF_STRG102f_Select_Positionsvorgabe
      SP_IF_STRG102f_Soll_Position_XIX_ClimateControl_VR_XIX_Innenraumheizenelektrisch_XIX_Zone_VR: provided-interface=IF_STRG102f_Soll_Position
      SP_IF_STRG102f_Spulenhaltebestromung_XIX_ClimateControl_VR_XIX_Innenraumheizenelektrisch_XIX_Zone_VR: provided-interface=IF_STRG102f_Spulenhaltebestromung
      SP_IF_STRG102f_Start_Position_XIX_ClimateControl_VR_XIX_Innenraumheizenelektrisch_XIX_Zone_VR: provided-interface=IF_STRG102f_Start_Position
      SP_IF_STRG102f_Stopmodus_XIX_ClimateControl_VR_XIX_Innenraumheizenelektrisch_XIX_Zone_VR: provided-interface=IF_STRG102f_Stopmodus
      SP_IF_STRG104a_Adresse_XIX_ClimateControl_VR_XIX_Innenraumheizenelektrisch_XIX_Zone_VR: provided-interface=IF_STRG104a_Adresse
      SP_IF_STRG104a_Clear_Event_Flags_XIX_ClimateControl_VR_XIX_Innenraumheizenelektrisch_XIX_Zone_VR: provided-interface=IF_STRG104a_Clear_Event_Flags
      SP_IF_STRG104a_Drehrichtung_XIX_ClimateControl_VR_XIX_Innenraumheizenelektrisch_XIX_Zone_VR: provided-interface=IF_STRG104a_Drehrichtung
      SP_IF_STRG104a_Freig_Blockiererkennung_XIX_ClimateControl_VR_XIX_Innenraumheizenelektrisch_XIX_Zone_VR: provided-interface=IF_STRG104a_Freig_Blockiererkennung
      SP_IF_STRG104a_Geschwindigkeitsvorgabe_XIX_ClimateControl_VR_XIX_Innenraumheizenelektrisch_XIX_Zone_VR: provided-interface=IF_STRG104a_Geschwindigkeitsvorgabe
      SP_IF_STRG104a_Notlauffreigabe_XIX_ClimateControl_VR_XIX_Innenraumheizenelektrisch_XIX_Zone_VR: provided-interface=IF_STRG104a_Notlauffreigabe
      SP_IF_STRG104a_Notlaufposition_XIX_ClimateControl_VR_XIX_Innenraumheizenelektrisch_XIX_Zone_VR: provided-interface=IF_STRG104a_Notlaufposition
      SP_IF_STRG104a_PrgDaten_speichern_XIX_ClimateControl_VR_XIX_Innenraumheizenelektrisch_XIX_Zone_VR: provided-interface=IF_STRG104a_PrgDaten_speichern
      SP_IF_STRG104a_Select_Positionsvorgabe_XIX_ClimateControl_VR_XIX_Innenraumheizenelektrisch_XIX_Zone_VR: provided-interface=IF_STRG104a_Select_Positionsvorgabe
      SP_IF_STRG104a_Soll_Position_XIX_ClimateControl_VR_XIX_Innenraumheizenelektrisch_XIX_Zone_VR: provided-interface=IF_STRG104a_Soll_Position
      SP_IF_STRG104a_Spulenhaltebestromung_XIX_ClimateControl_VR_XIX_Innenraumheizenelektrisch_XIX_Zone_VR: provided-interface=IF_STRG104a_Spulenhaltebestromung
      SP_IF_STRG104a_Start_Position_XIX_ClimateControl_VR_XIX_Innenraumheizenelektrisch_XIX_Zone_VR: provided-interface=IF_STRG104a_Start_Position
      SP_IF_STRG104a_Stopmodus_XIX_ClimateControl_VR_XIX_Innenraumheizenelektrisch_XIX_Zone_VR: provided-interface=IF_STRG104a_Stopmodus
      SP_IF_STRG105a_Adresse_XIX_ClimateControl_VR_XIX_Innenraumheizenelektrisch_XIX_Zone_VR: provided-interface=IF_STRG105a_Adresse
      SP_IF_STRG105a_Clear_Event_Flags_XIX_ClimateControl_VR_XIX_Innenraumheizenelektrisch_XIX_Zone_VR: provided-interface=IF_STRG105a_Clear_Event_Flags
      SP_IF_STRG105a_Drehrichtung_XIX_ClimateControl_VR_XIX_Innenraumheizenelektrisch_XIX_Zone_VR: provided-interface=IF_STRG105a_Drehrichtung
      SP_IF_STRG105a_Freig_Blockiererkennung_XIX_ClimateControl_VR_XIX_Innenraumheizenelektrisch_XIX_Zone_VR: provided-interface=IF_STRG105a_Freig_Blockiererkennung
      SP_IF_STRG105a_Geschwindigkeitsvorgabe_XIX_ClimateControl_VR_XIX_Innenraumheizenelektrisch_XIX_Zone_VR: provided-interface=IF_STRG105a_Geschwindigkeitsvorgabe
      SP_IF_STRG105a_Notlauffreigabe_XIX_ClimateControl_VR_XIX_Innenraumheizenelektrisch_XIX_Zone_VR: provided-interface=IF_STRG105a_Notlauffreigabe
      SP_IF_STRG105a_Notlaufposition_XIX_ClimateControl_VR_XIX_Innenraumheizenelektrisch_XIX_Zone_VR: provided-interface=IF_STRG105a_Notlaufposition
      SP_IF_STRG105a_PrgDaten_speichern_XIX_ClimateControl_VR_XIX_Innenraumheizenelektrisch_XIX_Zone_VR: provided-interface=IF_STRG105a_PrgDaten_speichern
      SP_IF_STRG105a_Select_Positionsvorgabe_XIX_ClimateControl_VR_XIX_Innenraumheizenelektrisch_XIX_Zone_VR: provided-interface=IF_STRG105a_Select_Positionsvorgabe
      SP_IF_STRG105a_Soll_Position_XIX_ClimateControl_VR_XIX_Innenraumheizenelektrisch_XIX_Zone_VR: provided-interface=IF_STRG105a_Soll_Position
      SP_IF_STRG105a_Spulenhaltebestromung_XIX_ClimateControl_VR_XIX_Innenraumheizenelektrisch_XIX_Zone_VR: provided-interface=IF_STRG105a_Spulenhaltebestromung
      SP_IF_STRG105a_Start_Position_XIX_ClimateControl_VR_XIX_Innenraumheizenelektrisch_XIX_Zone_VR: provided-interface=IF_STRG105a_Start_Position
      SP_IF_STRG105a_Stopmodus_XIX_ClimateControl_VR_XIX_Innenraumheizenelektrisch_XIX_Zone_VR: provided-interface=IF_STRG105a_Stopmodus
      SP_IF_STRG106a_Adresse_XIX_ClimateControl_VR_XIX_Innenraumheizenelektrisch_XIX_Zone_VR: provided-interface=IF_STRG106a_Adresse
      SP_IF_STRG106a_Clear_Event_Flags_XIX_ClimateControl_VR_XIX_Innenraumheizenelektrisch_XIX_Zone_VR: provided-interface=IF_STRG106a_Clear_Event_Flags
      SP_IF_STRG106a_Drehrichtung_XIX_ClimateControl_VR_XIX_Innenraumheizenelektrisch_XIX_Zone_VR: provided-interface=IF_STRG106a_Drehrichtung
      SP_IF_STRG106a_Freig_Blockiererkennung_XIX_ClimateControl_VR_XIX_Innenraumheizenelektrisch_XIX_Zone_VR: provided-interface=IF_STRG106a_Freig_Blockiererkennung
      SP_IF_STRG106a_Geschwindigkeitsvorgabe_XIX_ClimateControl_VR_XIX_Innenraumheizenelektrisch_XIX_Zone_VR: provided-interface=IF_STRG106a_Geschwindigkeitsvorgabe
      SP_IF_STRG106a_Notlauffreigabe_XIX_ClimateControl_VR_XIX_Innenraumheizenelektrisch_XIX_Zone_VR: provided-interface=IF_STRG106a_Notlauffreigabe
      SP_IF_STRG106a_Notlaufposition_XIX_ClimateControl_VR_XIX_Innenraumheizenelektrisch_XIX_Zone_VR: provided-interface=IF_STRG106a_Notlaufposition
      SP_IF_STRG106a_PrgDaten_speichern_XIX_ClimateControl_VR_XIX_Innenraumheizenelektrisch_XIX_Zone_VR: provided-interface=IF_STRG106a_PrgDaten_speichern
      SP_IF_STRG106a_Select_Positionsvorgabe_XIX_ClimateControl_VR_XIX_Innenraumheizenelektrisch_XIX_Zone_VR: provided-interface=IF_STRG106a_Select_Positionsvorgabe
      SP_IF_STRG106a_Soll_Position_XIX_ClimateControl_VR_XIX_Innenraumheizenelektrisch_XIX_Zone_VR: provided-interface=IF_STRG106a_Soll_Position
      SP_IF_STRG106a_Spulenhaltebestromung_XIX_ClimateControl_VR_XIX_Innenraumheizenelektrisch_XIX_Zone_VR: provided-interface=IF_STRG106a_Spulenhaltebestromung
      SP_IF_STRG106a_Start_Position_XIX_ClimateControl_VR_XIX_Innenraumheizenelektrisch_XIX_Zone_VR: provided-interface=IF_STRG106a_Start_Position
      SP_IF_STRG106a_Stopmodus_XIX_ClimateControl_VR_XIX_Innenraumheizenelektrisch_XIX_Zone_VR: provided-interface=IF_STRG106a_Stopmodus
      SP_IF_STRG109a_Adresse_XIX_ClimateControl_VR_XIX_Innenraumheizenelektrisch_XIX_Zone_VR: provided-interface=IF_STRG109a_Adresse
      SP_IF_STRG109a_Clear_Event_Flags_XIX_ClimateControl_VR_XIX_Innenraumheizenelektrisch_XIX_Zone_VR: provided-interface=IF_STRG109a_Clear_Event_Flags
      SP_IF_STRG109a_Drehrichtung_XIX_ClimateControl_VR_XIX_Innenraumheizenelektrisch_XIX_Zone_VR: provided-interface=IF_STRG109a_Drehrichtung
      SP_IF_STRG109a_Freig_Blockiererkennung_XIX_ClimateControl_VR_XIX_Innenraumheizenelektrisch_XIX_Zone_VR: provided-interface=IF_STRG109a_Freig_Blockiererkennung
      SP_IF_STRG109a_Geschwindigkeitsvorgabe_XIX_ClimateControl_VR_XIX_Innenraumheizenelektrisch_XIX_Zone_VR: provided-interface=IF_STRG109a_Geschwindigkeitsvorgabe
      SP_IF_STRG109a_Notlauffreigabe_XIX_ClimateControl_VR_XIX_Innenraumheizenelektrisch_XIX_Zone_VR: provided-interface=IF_STRG109a_Notlauffreigabe
      SP_IF_STRG109a_Notlaufposition_XIX_ClimateControl_VR_XIX_Innenraumheizenelektrisch_XIX_Zone_VR: provided-interface=IF_STRG109a_Notlaufposition
      SP_IF_STRG109a_PrgDaten_speichern_XIX_ClimateControl_VR_XIX_Innenraumheizenelektrisch_XIX_Zone_VR: provided-interface=IF_STRG109a_PrgDaten_speichern
      SP_IF_STRG109a_Select_Positionsvorgabe_XIX_ClimateControl_VR_XIX_Innenraumheizenelektrisch_XIX_Zone_VR: provided-interface=IF_STRG109a_Select_Positionsvorgabe
      SP_IF_STRG109a_Soll_Position_XIX_ClimateControl_VR_XIX_Innenraumheizenelektrisch_XIX_Zone_VR: provided-interface=IF_STRG109a_Soll_Position
      SP_IF_STRG109a_Spulenhaltebestromung_XIX_ClimateControl_VR_XIX_Innenraumheizenelektrisch_XIX_Zone_VR: provided-interface=IF_STRG109a_Spulenhaltebestromung
      SP_IF_STRG109a_Start_Position_XIX_ClimateControl_VR_XIX_Innenraumheizenelektrisch_XIX_Zone_VR: provided-interface=IF_STRG109a_Start_Position
      SP_IF_STRG109a_Stopmodus_XIX_ClimateControl_VR_XIX_Innenraumheizenelektrisch_XIX_Zone_VR: provided-interface=IF_STRG109a_Stopmodus
    163 x require port:
      RP_IF_ACT102f_Adresse_Aktuator_XIX_ClimateControl_VR_XIX_Innenraumheizenelektrisch_XIX_Zone_VR: required-interface=IF_ACT102f_Adresse_Aktuator
      RP_IF_ACT102f_Blockierung_aufgetreten_XIX_ClimateControl_VR_XIX_Innenraumheizenelektrisch_XIX_Zone_VR: required-interface=IF_ACT102f_Blockierung_aufgetreten
      RP_IF_ACT102f_Drehrichtung_XIX_ClimateControl_VR_XIX_Innenraumheizenelektrisch_XIX_Zone_VR: required-interface=IF_ACT102f_Drehrichtung
      RP_IF_ACT102f_Geschwindigkeitsstatus_XIX_ClimateControl_VR_XIX_Innenraumheizenelektrisch_XIX_Zone_VR: required-interface=IF_ACT102f_Geschwindigkeitsstatus
      RP_IF_ACT102f_Ist_Position_Aktuator_XIX_ClimateControl_VR_XIX_Innenraumheizenelektrisch_XIX_Zone_VR: required-interface=IF_ACT102f_Ist_Position_Aktuator
      RP_IF_ACT102f_Notlauf_aufgetreten_XIX_ClimateControl_VR_XIX_Innenraumheizenelektrisch_XIX_Zone_VR: required-interface=IF_ACT102f_Notlauf_aufgetreten
      RP_IF_ACT102f_Notlauffreigabe_XIX_ClimateControl_VR_XIX_Innenraumheizenelektrisch_XIX_Zone_VR: required-interface=IF_ACT102f_Notlauffreigabe
      RP_IF_ACT102f_Notlaufposition_XIX_ClimateControl_VR_XIX_Innenraumheizenelektrisch_XIX_Zone_VR: required-interface=IF_ACT102f_Notlaufposition
      RP_IF_ACT102f_Positionsvorgabe_Status_XIX_ClimateControl_VR_XIX_Innenraumheizenelektrisch_XIX_Zone_VR: required-interface=IF_ACT102f_Positionsvorgabe_Status
      RP_IF_ACT102f_Reset_XIX_ClimateControl_VR_XIX_Innenraumheizenelektrisch_XIX_Zone_VR: required-interface=IF_ACT102f_Reset
      RP_IF_ACT102f_Selbsthaltemoment_XIX_ClimateControl_VR_XIX_Innenraumheizenelektrisch_XIX_Zone_VR: required-interface=IF_ACT102f_Selbsthaltemoment
      RP_IF_ACT102f_Sonderfunktionen_XIX_ClimateControl_VR_XIX_Innenraumheizenelektrisch_XIX_Zone_VR: required-interface=IF_ACT102f_Sonderfunktionen
      RP_IF_ACT102f_Spulenbestromung_XIX_ClimateControl_VR_XIX_Innenraumheizenelektrisch_XIX_Zone_VR: required-interface=IF_ACT102f_Spulenbestromung
      RP_IF_ACT102f_Stopmodus_XIX_ClimateControl_VR_XIX_Innenraumheizenelektrisch_XIX_Zone_VR: required-interface=IF_ACT102f_Stopmodus
      RP_IF_ACT102f_Uebertemperatur_XIX_ClimateControl_VR_XIX_Innenraumheizenelektrisch_XIX_Zone_VR: required-interface=IF_ACT102f_Uebertemperatur
      RP_IF_ACT102f_Variante_XIX_ClimateControl_VR_XIX_Innenraumheizenelektrisch_XIX_Zone_VR: required-interface=IF_ACT102f_Variante
      RP_IF_ACT102f_Verfahrrichtung_XIX_ClimateControl_VR_XIX_Innenraumheizenelektrisch_XIX_Zone_VR: required-interface=IF_ACT102f_Verfahrrichtung
      RP_IF_ACT102f_Versorgungsspannung_XIX_ClimateControl_VR_XIX_Innenraumheizenelektrisch_XIX_Zone_VR: required-interface=IF_ACT102f_Versorgungsspannung
      RP_IF_ACT102f_el_Defekt_XIX_ClimateControl_VR_XIX_Innenraumheizenelektrisch_XIX_Zone_VR: required-interface=IF_ACT102f_el_Defekt
      RP_IF_ACT104a_Adresse_Aktuator_XIX_ClimateControl_VR_XIX_Innenraumheizenelektrisch_XIX_Zone_VR: required-interface=IF_ACT104a_Adresse_Aktuator
      RP_IF_ACT104a_Blockierung_aufgetreten_XIX_ClimateControl_VR_XIX_Innenraumheizenelektrisch_XIX_Zone_VR: required-interface=IF_ACT104a_Blockierung_aufgetreten
      RP_IF_ACT104a_Drehrichtung_XIX_ClimateControl_VR_XIX_Innenraumheizenelektrisch_XIX_Zone_VR: required-interface=IF_ACT104a_Drehrichtung
      RP_IF_ACT104a_Geschwindigkeitsstatus_XIX_ClimateControl_VR_XIX_Innenraumheizenelektrisch_XIX_Zone_VR: required-interface=IF_ACT104a_Geschwindigkeitsstatus
      RP_IF_ACT104a_Ist_Position_Aktuator_XIX_ClimateControl_VR_XIX_Innenraumheizenelektrisch_XIX_Zone_VR: required-interface=IF_ACT104a_Ist_Position_Aktuator
      RP_IF_ACT104a_Notlauf_aufgetreten_XIX_ClimateControl_VR_XIX_Innenraumheizenelektrisch_XIX_Zone_VR: required-interface=IF_ACT104a_Notlauf_aufgetreten
      RP_IF_ACT104a_Notlauffreigabe_XIX_ClimateControl_VR_XIX_Innenraumheizenelektrisch_XIX_Zone_VR: required-interface=IF_ACT104a_Notlauffreigabe
      RP_IF_ACT104a_Notlaufposition_XIX_ClimateControl_VR_XIX_Innenraumheizenelektrisch_XIX_Zone_VR: required-interface=IF_ACT104a_Notlaufposition
      RP_IF_ACT104a_Positionsvorgabe_Status_XIX_ClimateControl_VR_XIX_Innenraumheizenelektrisch_XIX_Zone_VR: required-interface=IF_ACT104a_Positionsvorgabe_Status
      RP_IF_ACT104a_Reset_XIX_ClimateControl_VR_XIX_Innenraumheizenelektrisch_XIX_Zone_VR: required-interface=IF_ACT104a_Reset
      RP_IF_ACT104a_Selbsthaltemoment_XIX_ClimateControl_VR_XIX_Innenraumheizenelektrisch_XIX_Zone_VR: required-interface=IF_ACT104a_Selbsthaltemoment
      RP_IF_ACT104a_Sonderfunktionen_XIX_ClimateControl_VR_XIX_Innenraumheizenelektrisch_XIX_Zone_VR: required-interface=IF_ACT104a_Sonderfunktionen
      RP_IF_ACT104a_Spulenbestromung_XIX_ClimateControl_VR_XIX_Innenraumheizenelektrisch_XIX_Zone_VR: required-interface=IF_ACT104a_Spulenbestromung
      RP_IF_ACT104a_Stopmodus_XIX_ClimateControl_VR_XIX_Innenraumheizenelektrisch_XIX_Zone_VR: required-interface=IF_ACT104a_Stopmodus
      RP_IF_ACT104a_Uebertemperatur_XIX_ClimateControl_VR_XIX_Innenraumheizenelektrisch_XIX_Zone_VR: required-interface=IF_ACT104a_Uebertemperatur
      RP_IF_ACT104a_Variante_XIX_ClimateControl_VR_XIX_Innenraumheizenelektrisch_XIX_Zone_VR: required-interface=IF_ACT104a_Variante
      RP_IF_ACT104a_Verfahrrichtung_XIX_ClimateControl_VR_XIX_Innenraumheizenelektrisch_XIX_Zone_VR: required-interface=IF_ACT104a_Verfahrrichtung
      RP_IF_ACT104a_Versorgungsspannung_XIX_ClimateControl_VR_XIX_Innenraumheizenelektrisch_XIX_Zone_VR: required-interface=IF_ACT104a_Versorgungsspannung
      RP_IF_ACT104a_el_Defekt_XIX_ClimateControl_VR_XIX_Innenraumheizenelektrisch_XIX_Zone_VR: required-interface=IF_ACT104a_el_Defekt
      RP_IF_ACT105a_Adresse_Aktuator_XIX_ClimateControl_VR_XIX_Innenraumheizenelektrisch_XIX_Zone_VR: required-interface=IF_ACT105a_Adresse_Aktuator
      RP_IF_ACT105a_Blockierung_aufgetreten_XIX_ClimateControl_VR_XIX_Innenraumheizenelektrisch_XIX_Zone_VR: required-interface=IF_ACT105a_Blockierung_aufgetreten
      RP_IF_ACT105a_Drehrichtung_XIX_ClimateControl_VR_XIX_Innenraumheizenelektrisch_XIX_Zone_VR: required-interface=IF_ACT105a_Drehrichtung
      RP_IF_ACT105a_Geschwindigkeitsstatus_XIX_ClimateControl_VR_XIX_Innenraumheizenelektrisch_XIX_Zone_VR: required-interface=IF_ACT105a_Geschwindigkeitsstatus
      RP_IF_ACT105a_Ist_Position_Aktuator_XIX_ClimateControl_VR_XIX_Innenraumheizenelektrisch_XIX_Zone_VR: required-interface=IF_ACT105a_Ist_Position_Aktuator
      RP_IF_ACT105a_Notlauf_aufgetreten_XIX_ClimateControl_VR_XIX_Innenraumheizenelektrisch_XIX_Zone_VR: required-interface=IF_ACT105a_Notlauf_aufgetreten
      RP_IF_ACT105a_Notlauffreigabe_XIX_ClimateControl_VR_XIX_Innenraumheizenelektrisch_XIX_Zone_VR: required-interface=IF_ACT105a_Notlauffreigabe
      RP_IF_ACT105a_Notlaufposition_XIX_ClimateControl_VR_XIX_Innenraumheizenelektrisch_XIX_Zone_VR: required-interface=IF_ACT105a_Notlaufposition
      RP_IF_ACT105a_Positionsvorgabe_Status_XIX_ClimateControl_VR_XIX_Innenraumheizenelektrisch_XIX_Zone_VR: required-interface=IF_ACT105a_Positionsvorgabe_Status
      RP_IF_ACT105a_Reset_XIX_ClimateControl_VR_XIX_Innenraumheizenelektrisch_XIX_Zone_VR: required-interface=IF_ACT105a_Reset
      RP_IF_ACT105a_Selbsthaltemoment_XIX_ClimateControl_VR_XIX_Innenraumheizenelektrisch_XIX_Zone_VR: required-interface=IF_ACT105a_Selbsthaltemoment
      RP_IF_ACT105a_Sonderfunktionen_XIX_ClimateControl_VR_XIX_Innenraumheizenelektrisch_XIX_Zone_VR: required-interface=IF_ACT105a_Sonderfunktionen
      RP_IF_ACT105a_Spulenbestromung_XIX_ClimateControl_VR_XIX_Innenraumheizenelektrisch_XIX_Zone_VR: required-interface=IF_ACT105a_Spulenbestromung
      RP_IF_ACT105a_Stopmodus_XIX_ClimateControl_VR_XIX_Innenraumheizenelektrisch_XIX_Zone_VR: required-interface=IF_ACT105a_Stopmodus
      RP_IF_ACT105a_Uebertemperatur_XIX_ClimateControl_VR_XIX_Innenraumheizenelektrisch_XIX_Zone_VR: required-interface=IF_ACT105a_Uebertemperatur
      RP_IF_ACT105a_Variante_XIX_ClimateControl_VR_XIX_Innenraumheizenelektrisch_XIX_Zone_VR: required-interface=IF_ACT105a_Variante
      RP_IF_ACT105a_Verfahrrichtung_XIX_ClimateControl_VR_XIX_Innenraumheizenelektrisch_XIX_Zone_VR: required-interface=IF_ACT105a_Verfahrrichtung
      RP_IF_ACT105a_Versorgungsspannung_XIX_ClimateControl_VR_XIX_Innenraumheizenelektrisch_XIX_Zone_VR: required-interface=IF_ACT105a_Versorgungsspannung
      RP_IF_ACT105a_el_Defekt_XIX_ClimateControl_VR_XIX_Innenraumheizenelektrisch_XIX_Zone_VR: required-interface=IF_ACT105a_el_Defekt
      RP_IF_ACT106a_Adresse_Aktuator_XIX_ClimateControl_VR_XIX_Innenraumheizenelektrisch_XIX_Zone_VR: required-interface=IF_ACT106a_Adresse_Aktuator
      RP_IF_ACT106a_Blockierung_aufgetreten_XIX_ClimateControl_VR_XIX_Innenraumheizenelektrisch_XIX_Zone_VR: required-interface=IF_ACT106a_Blockierung_aufgetreten
      RP_IF_ACT106a_Drehrichtung_XIX_ClimateControl_VR_XIX_Innenraumheizenelektrisch_XIX_Zone_VR: required-interface=IF_ACT106a_Drehrichtung
      RP_IF_ACT106a_Geschwindigkeitsstatus_XIX_ClimateControl_VR_XIX_Innenraumheizenelektrisch_XIX_Zone_VR: required-interface=IF_ACT106a_Geschwindigkeitsstatus
      RP_IF_ACT106a_Ist_Position_Aktuator_XIX_ClimateControl_VR_XIX_Innenraumheizenelektrisch_XIX_Zone_VR: required-interface=IF_ACT106a_Ist_Position_Aktuator
      RP_IF_ACT106a_Notlauf_aufgetreten_XIX_ClimateControl_VR_XIX_Innenraumheizenelektrisch_XIX_Zone_VR: required-interface=IF_ACT106a_Notlauf_aufgetreten
      RP_IF_ACT106a_Notlauffreigabe_XIX_ClimateControl_VR_XIX_Innenraumheizenelektrisch_XIX_Zone_VR: required-interface=IF_ACT106a_Notlauffreigabe
      RP_IF_ACT106a_Notlaufposition_XIX_ClimateControl_VR_XIX_Innenraumheizenelektrisch_XIX_Zone_VR: required-interface=IF_ACT106a_Notlaufposition
      RP_IF_ACT106a_Positionsvorgabe_Status_XIX_ClimateControl_VR_XIX_Innenraumheizenelektrisch_XIX_Zone_VR: required-interface=IF_ACT106a_Positionsvorgabe_Status
      RP_IF_ACT106a_Reset_XIX_ClimateControl_VR_XIX_Innenraumheizenelektrisch_XIX_Zone_VR: required-interface=IF_ACT106a_Reset
      RP_IF_ACT106a_Selbsthaltemoment_XIX_ClimateControl_VR_XIX_Innenraumheizenelektrisch_XIX_Zone_VR: required-interface=IF_ACT106a_Selbsthaltemoment
      RP_IF_ACT106a_Sonderfunktionen_XIX_ClimateControl_VR_XIX_Innenraumheizenelektrisch_XIX_Zone_VR: required-interface=IF_ACT106a_Sonderfunktionen
      RP_IF_ACT106a_Spulenbestromung_XIX_ClimateControl_VR_XIX_Innenraumheizenelektrisch_XIX_Zone_VR: required-interface=IF_ACT106a_Spulenbestromung
      RP_IF_ACT106a_Stopmodus_XIX_ClimateControl_VR_XIX_Innenraumheizenelektrisch_XIX_Zone_VR: required-interface=IF_ACT106a_Stopmodus
      RP_IF_ACT106a_Uebertemperatur_XIX_ClimateControl_VR_XIX_Innenraumheizenelektrisch_XIX_Zone_VR: required-interface=IF_ACT106a_Uebertemperatur
      RP_IF_ACT106a_Variante_XIX_ClimateControl_VR_XIX_Innenraumheizenelektrisch_XIX_Zone_VR: required-interface=IF_ACT106a_Variante
      RP_IF_ACT106a_Verfahrrichtung_XIX_ClimateControl_VR_XIX_Innenraumheizenelektrisch_XIX_Zone_VR: required-interface=IF_ACT106a_Verfahrrichtung
      RP_IF_ACT106a_Versorgungsspannung_XIX_ClimateControl_VR_XIX_Innenraumheizenelektrisch_XIX_Zone_VR: required-interface=IF_ACT106a_Versorgungsspannung
      RP_IF_ACT106a_el_Defekt_XIX_ClimateControl_VR_XIX_Innenraumheizenelektrisch_XIX_Zone_VR: required-interface=IF_ACT106a_el_Defekt
      RP_IF_ACT109a_Adresse_Aktuator_XIX_ClimateControl_VR_XIX_Innenraumheizenelektrisch_XIX_Zone_VR: required-interface=IF_ACT109a_Adresse_Aktuator
      RP_IF_ACT109a_Blockierung_aufgetreten_XIX_ClimateControl_VR_XIX_Innenraumheizenelektrisch_XIX_Zone_VR: required-interface=IF_ACT109a_Blockierung_aufgetreten
      RP_IF_ACT109a_Drehrichtung_XIX_ClimateControl_VR_XIX_Innenraumheizenelektrisch_XIX_Zone_VR: required-interface=IF_ACT109a_Drehrichtung
      RP_IF_ACT109a_Geschwindigkeitsstatus_XIX_ClimateControl_VR_XIX_Innenraumheizenelektrisch_XIX_Zone_VR: required-interface=IF_ACT109a_Geschwindigkeitsstatus
      RP_IF_ACT109a_Ist_Position_Aktuator_XIX_ClimateControl_VR_XIX_Innenraumheizenelektrisch_XIX_Zone_VR: required-interface=IF_ACT109a_Ist_Position_Aktuator
      RP_IF_ACT109a_Notlauf_aufgetreten_XIX_ClimateControl_VR_XIX_Innenraumheizenelektrisch_XIX_Zone_VR: required-interface=IF_ACT109a_Notlauf_aufgetreten
      RP_IF_ACT109a_Notlauffreigabe_XIX_ClimateControl_VR_XIX_Innenraumheizenelektrisch_XIX_Zone_VR: required-interface=IF_ACT109a_Notlauffreigabe
      RP_IF_ACT109a_Notlaufposition_XIX_ClimateControl_VR_XIX_Innenraumheizenelektrisch_XIX_Zone_VR: required-interface=IF_ACT109a_Notlaufposition
      RP_IF_ACT109a_Positionsvorgabe_Status_XIX_ClimateControl_VR_XIX_Innenraumheizenelektrisch_XIX_Zone_VR: required-interface=IF_ACT109a_Positionsvorgabe_Status
      RP_IF_ACT109a_Reset_XIX_ClimateControl_VR_XIX_Innenraumheizenelektrisch_XIX_Zone_VR: required-interface=IF_ACT109a_Reset
      RP_IF_ACT109a_Selbsthaltemoment_XIX_ClimateControl_VR_XIX_Innenraumheizenelektrisch_XIX_Zone_VR: required-interface=IF_ACT109a_Selbsthaltemoment
      RP_IF_ACT109a_Sonderfunktionen_XIX_ClimateControl_VR_XIX_Innenraumheizenelektrisch_XIX_Zone_VR: required-interface=IF_ACT109a_Sonderfunktionen
      RP_IF_ACT109a_Spulenbestromung_XIX_ClimateControl_VR_XIX_Innenraumheizenelektrisch_XIX_Zone_VR: required-interface=IF_ACT109a_Spulenbestromung
      RP_IF_ACT109a_Stopmodus_XIX_ClimateControl_VR_XIX_Innenraumheizenelektrisch_XIX_Zone_VR: required-interface=IF_ACT109a_Stopmodus
      RP_IF_ACT109a_Uebertemperatur_XIX_ClimateControl_VR_XIX_Innenraumheizenelektrisch_XIX_Zone_VR: required-interface=IF_ACT109a_Uebertemperatur
      RP_IF_ACT109a_Variante_XIX_ClimateControl_VR_XIX_Innenraumheizenelektrisch_XIX_Zone_VR: required-interface=IF_ACT109a_Variante
      RP_IF_ACT109a_Verfahrrichtung_XIX_ClimateControl_VR_XIX_Innenraumheizenelektrisch_XIX_Zone_VR: required-interface=IF_ACT109a_Verfahrrichtung
      RP_IF_ACT109a_Versorgungsspannung_XIX_ClimateControl_VR_XIX_Innenraumheizenelektrisch_XIX_Zone_VR: required-interface=IF_ACT109a_Versorgungsspannung
      RP_IF_ACT109a_el_Defekt_XIX_ClimateControl_VR_XIX_Innenraumheizenelektrisch_XIX_Zone_VR: required-interface=IF_ACT109a_el_Defekt
      RP_IF_BLOWER_DIAG_FLAG1_XIX_ClimateControl_VR_XIX_Innenraumheizenelektrisch_XIX_Zone_VR: required-interface=IF_BLOWER_DIAG_FLAG1
      RP_IF_BLOWER_DIAG_FLAG2_XIX_ClimateControl_VR_XIX_Innenraumheizenelektrisch_XIX_Zone_VR: required-interface=IF_BLOWER_DIAG_FLAG2
      RP_IF_BLOWER_IBATT_XIX_ClimateControl_VR_XIX_Innenraumheizenelektrisch_XIX_Zone_VR: required-interface=IF_BLOWER_IBATT
      RP_IF_BLOWER_ROTATION_SPEED_XIX_ClimateControl_VR_XIX_Innenraumheizenelektrisch_XIX_Zone_VR: required-interface=IF_BLOWER_ROTATION_SPEED
      RP_IF_BLOWER_STATUS_MOTOR_XIX_ClimateControl_VR_XIX_Innenraumheizenelektrisch_XIX_Zone_VR: required-interface=IF_BLOWER_STATUS_MOTOR
      RP_IF_BLOWER_SUPPLIER_XIX_ClimateControl_VR_XIX_Innenraumheizenelektrisch_XIX_Zone_VR: required-interface=IF_BLOWER_SUPPLIER
      RP_IF_BLOWER_TEMPERATURE_XIX_ClimateControl_VR_XIX_Innenraumheizenelektrisch_XIX_Zone_VR: required-interface=IF_BLOWER_TEMPERATURE
      RP_IF_BLOWER_TORQUE_XIX_ClimateControl_VR_XIX_Innenraumheizenelektrisch_XIX_Zone_VR: required-interface=IF_BLOWER_TORQUE
      RP_IF_BLOWER_UBATT_XIX_ClimateControl_VR_XIX_Innenraumheizenelektrisch_XIX_Zone_VR: required-interface=IF_BLOWER_UBATT
      RP_IF_BLOWER_UMOTOR_XIX_ClimateControl_VR_XIX_Innenraumheizenelektrisch_XIX_Zone_VR: required-interface=IF_BLOWER_UMOTOR
      RP_IF_ClActFan_perc_BlowerTarVal_S_XIX_ClimateControl_VR_XIX_Innenraumheizenelektrisch_XIX_Zone_VR: required-interface=IF_ClActFan_perc_BlowerTarVal_S
      RP_IF_ClAct_perc_FlapDfrstTarVal_XIX_ClimateControl_VR_XIX_Innenraumheizenelektrisch_XIX_Zone_VR: required-interface=IF_ClAct_perc_FlapDfrstTarVal
      RP_IF_ClAct_perc_FlapTFrntLeTarVal_XIX_ClimateControl_VR_XIX_Innenraumheizenelektrisch_XIX_Zone_VR: required-interface=IF_ClAct_perc_FlapTFrntLeTarVal
      RP_IF_ClAct_perc_FlapTFrntRiTarVal_XIX_ClimateControl_VR_XIX_Innenraumheizenelektrisch_XIX_Zone_VR: required-interface=IF_ClAct_perc_FlapTFrntRiTarVal
      RP_IF_ClAct_perc_FlapTRearLeTarVal_XIX_ClimateControl_VR_XIX_Innenraumheizenelektrisch_XIX_Zone_VR: required-interface=IF_ClAct_perc_FlapTRearLeTarVal
      RP_IF_ClAct_perc_FlapTRearRiTarVal_XIX_ClimateControl_VR_XIX_Innenraumheizenelektrisch_XIX_Zone_VR: required-interface=IF_ClAct_perc_FlapTRearRiTarVal
      RP_IF_ClHmi_T_CurTempFrntLe_S_XIX_ClimateControl_VR_XIX_Innenraumheizenelektrisch_XIX_Zone_VR: required-interface=IF_ClHmi_T_CurTempFrntLe_S
      RP_IF_ClHmi_T_CurTempFrntRi_S_XIX_ClimateControl_VR_XIX_Innenraumheizenelektrisch_XIX_Zone_VR: required-interface=IF_ClHmi_T_CurTempFrntRi_S
      RP_IF_ClHmi_T_CurTempRearLe_S_XIX_ClimateControl_VR_XIX_Innenraumheizenelektrisch_XIX_Zone_VR: required-interface=IF_ClHmi_T_CurTempRearLe_S
      RP_IF_ClHmi_T_CurTempRearRi_S_XIX_ClimateControl_VR_XIX_Innenraumheizenelektrisch_XIX_Zone_VR: required-interface=IF_ClHmi_T_CurTempRearRi_S
      RP_IF_ClHmi_st_StDfrst_S_XIX_ClimateControl_VR_XIX_Innenraumheizenelektrisch_XIX_Zone_VR: required-interface=IF_ClHmi_st_StDfrst_S
      RP_IF_ClSens_SetBit1_S_XIX_ClimateControl_VR_XIX_Innenraumheizenelektrisch_XIX_Zone_VR: required-interface=IF_ClSens_SetBit1_S
      RP_IF_ClSens_SetBit2_S_XIX_ClimateControl_VR_XIX_Innenraumheizenelektrisch_XIX_Zone_VR: required-interface=IF_ClSens_SetBit2_S
      RP_IF_ClStm_OpState_XIX_ClimateControl_VR_XIX_Innenraumheizenelektrisch_XIX_Zone_VR: required-interface=IF_ClStm_OpState
      RP_IF_KL_DI_KL_58xd_XIX_ClimateControl_VR_XIX_Innenraumheizenelektrisch_XIX_Zone_VR: required-interface=IF_KL_DI_KL_58xd
      RP_IF_KL_DI_KL_58xs_XIX_ClimateControl_VR_XIX_Innenraumheizenelektrisch_XIX_Zone_VR: required-interface=IF_KL_DI_KL_58xs
      RP_IF_KL_KST_KL_15_XIX_ClimateControl_VR_XIX_Innenraumheizenelektrisch_XIX_Zone_VR: required-interface=IF_KL_KST_KL_15
      RP_IF_KPH_AC_XIX_ClimateControl_VR_XIX_Innenraumheizenelektrisch_XIX_Zone_VR: required-interface=IF_KPH_AC
      RP_IF_KPH_AC_max_XIX_ClimateControl_VR_XIX_Innenraumheizenelektrisch_XIX_Zone_VR: required-interface=IF_KPH_AC_max
      RP_IF_KPH_Auto_li_XIX_ClimateControl_VR_XIX_Innenraumheizenelektrisch_XIX_Zone_VR: required-interface=IF_KPH_Auto_li
      RP_IF_KPH_Auto_re_XIX_ClimateControl_VR_XIX_Innenraumheizenelektrisch_XIX_Zone_VR: required-interface=IF_KPH_Auto_re
      RP_IF_KPH_Beduftung_XIX_ClimateControl_VR_XIX_Innenraumheizenelektrisch_XIX_Zone_VR: required-interface=IF_KPH_Beduftung
      RP_IF_KPH_ECO_XIX_ClimateControl_VR_XIX_Innenraumheizenelektrisch_XIX_Zone_VR: required-interface=IF_KPH_ECO
      RP_IF_KPH_ECO_links_XIX_ClimateControl_VR_XIX_Innenraumheizenelektrisch_XIX_Zone_VR: required-interface=IF_KPH_ECO_links
      RP_IF_KPH_ECO_rechts_XIX_ClimateControl_VR_XIX_Innenraumheizenelektrisch_XIX_Zone_VR: required-interface=IF_KPH_ECO_rechts
      RP_IF_KPH_Flaechenheizung_XIX_ClimateControl_VR_XIX_Innenraumheizenelektrisch_XIX_Zone_VR: required-interface=IF_KPH_Flaechenheizung
      RP_IF_KPH_Geblaese_Auto_li_XIX_ClimateControl_VR_XIX_Innenraumheizenelektrisch_XIX_Zone_VR: required-interface=IF_KPH_Geblaese_Auto_li
      RP_IF_KPH_Geblaese_Auto_re_XIX_ClimateControl_VR_XIX_Innenraumheizenelektrisch_XIX_Zone_VR: required-interface=IF_KPH_Geblaese_Auto_re
      RP_IF_KPH_Geblaese_Stufe_li_XIX_ClimateControl_VR_XIX_Innenraumheizenelektrisch_XIX_Zone_VR: required-interface=IF_KPH_Geblaese_Stufe_li
      RP_IF_KPH_Geblaese_Stufe_re_XIX_ClimateControl_VR_XIX_Innenraumheizenelektrisch_XIX_Zone_VR: required-interface=IF_KPH_Geblaese_Stufe_re
      RP_IF_KPH_Init_XIX_ClimateControl_VR_XIX_Innenraumheizenelektrisch_XIX_Zone_VR: required-interface=IF_KPH_Init
      RP_IF_KPH_Ionisator_XIX_ClimateControl_VR_XIX_Innenraumheizenelektrisch_XIX_Zone_VR: required-interface=IF_KPH_Ionisator
      RP_IF_KPH_Klima_Menue_MMI_XIX_ClimateControl_VR_XIX_Innenraumheizenelektrisch_XIX_Zone_VR: required-interface=IF_KPH_Klima_Menue_MMI
      RP_IF_KPH_Lautsprecher_XIX_ClimateControl_VR_XIX_Innenraumheizenelektrisch_XIX_Zone_VR: required-interface=IF_KPH_Lautsprecher
      RP_IF_KPH_Lokalaktiv_XIX_ClimateControl_VR_XIX_Innenraumheizenelektrisch_XIX_Zone_VR: required-interface=IF_KPH_Lokalaktiv
      RP_IF_KPH_Luftverteilung_Auto_li_XIX_ClimateControl_VR_XIX_Innenraumheizenelektrisch_XIX_Zone_VR: required-interface=IF_KPH_Luftverteilung_Auto_li
      RP_IF_KPH_Luftverteilung_Auto_re_XIX_ClimateControl_VR_XIX_Innenraumheizenelektrisch_XIX_Zone_VR: required-interface=IF_KPH_Luftverteilung_Auto_re
      RP_IF_KPH_Luftverteilung_Mitte_li_XIX_ClimateControl_VR_XIX_Innenraumheizenelektrisch_XIX_Zone_VR: required-interface=IF_KPH_Luftverteilung_Mitte_li
      RP_IF_KPH_Luftverteilung_Mitte_re_XIX_ClimateControl_VR_XIX_Innenraumheizenelektrisch_XIX_Zone_VR: required-interface=IF_KPH_Luftverteilung_Mitte_re
      RP_IF_KPH_Luftverteilung_Oben_li_XIX_ClimateControl_VR_XIX_Innenraumheizenelektrisch_XIX_Zone_VR: required-interface=IF_KPH_Luftverteilung_Oben_li
      RP_IF_KPH_Luftverteilung_Oben_re_XIX_ClimateControl_VR_XIX_Innenraumheizenelektrisch_XIX_Zone_VR: required-interface=IF_KPH_Luftverteilung_Oben_re
      RP_IF_KPH_Luftverteilung_Unten_li_XIX_ClimateControl_VR_XIX_Innenraumheizenelektrisch_XIX_Zone_VR: required-interface=IF_KPH_Luftverteilung_Unten_li
      RP_IF_KPH_Luftverteilung_Unten_re_XIX_ClimateControl_VR_XIX_Innenraumheizenelektrisch_XIX_Zone_VR: required-interface=IF_KPH_Luftverteilung_Unten_re
      RP_IF_KPH_Neigungssensor_XIX_ClimateControl_VR_XIX_Innenraumheizenelektrisch_XIX_Zone_VR: required-interface=IF_KPH_Neigungssensor
      RP_IF_KPH_Off_XIX_ClimateControl_VR_XIX_Innenraumheizenelektrisch_XIX_Zone_VR: required-interface=IF_KPH_Off
      RP_IF_KPH_Panel_Error_XIX_ClimateControl_VR_XIX_Innenraumheizenelektrisch_XIX_Zone_VR: required-interface=IF_KPH_Panel_Error
      RP_IF_KPH_ResponseError_XIX_ClimateControl_VR_XIX_Innenraumheizenelektrisch_XIX_Zone_VR: required-interface=IF_KPH_ResponseError
      RP_IF_KPH_Sitzheizung_li_XIX_ClimateControl_VR_XIX_Innenraumheizenelektrisch_XIX_Zone_VR: required-interface=IF_KPH_Sitzheizung_li
      RP_IF_KPH_Sitzheizung_re_XIX_ClimateControl_VR_XIX_Innenraumheizenelektrisch_XIX_Zone_VR: required-interface=IF_KPH_Sitzheizung_re
      RP_IF_KPH_Sitzlueftung_li_XIX_ClimateControl_VR_XIX_Innenraumheizenelektrisch_XIX_Zone_VR: required-interface=IF_KPH_Sitzlueftung_li
      RP_IF_KPH_Sitzlueftung_re_XIX_ClimateControl_VR_XIX_Innenraumheizenelektrisch_XIX_Zone_VR: required-interface=IF_KPH_Sitzlueftung_re
      RP_IF_KPH_Status_Spannung_XIX_ClimateControl_VR_XIX_Innenraumheizenelektrisch_XIX_Zone_VR: required-interface=IF_KPH_Status_Spannung
      RP_IF_KPH_Sync_XIX_ClimateControl_VR_XIX_Innenraumheizenelektrisch_XIX_Zone_VR: required-interface=IF_KPH_Sync
      RP_IF_KPH_Tasten_Fehler_XIX_ClimateControl_VR_XIX_Innenraumheizenelektrisch_XIX_Zone_VR: required-interface=IF_KPH_Tasten_Fehler
      RP_IF_KPH_Temp_Platine_XIX_ClimateControl_VR_XIX_Innenraumheizenelektrisch_XIX_Zone_VR: required-interface=IF_KPH_Temp_Platine
      RP_IF_KPH_Temp_li_XIX_ClimateControl_VR_XIX_Innenraumheizenelektrisch_XIX_Zone_VR: required-interface=IF_KPH_Temp_li
      RP_IF_KPH_Temp_re_XIX_ClimateControl_VR_XIX_Innenraumheizenelektrisch_XIX_Zone_VR: required-interface=IF_KPH_Temp_re
      RP_IF_KPH_Umluft_XIX_ClimateControl_VR_XIX_Innenraumheizenelektrisch_XIX_Zone_VR: required-interface=IF_KPH_Umluft
